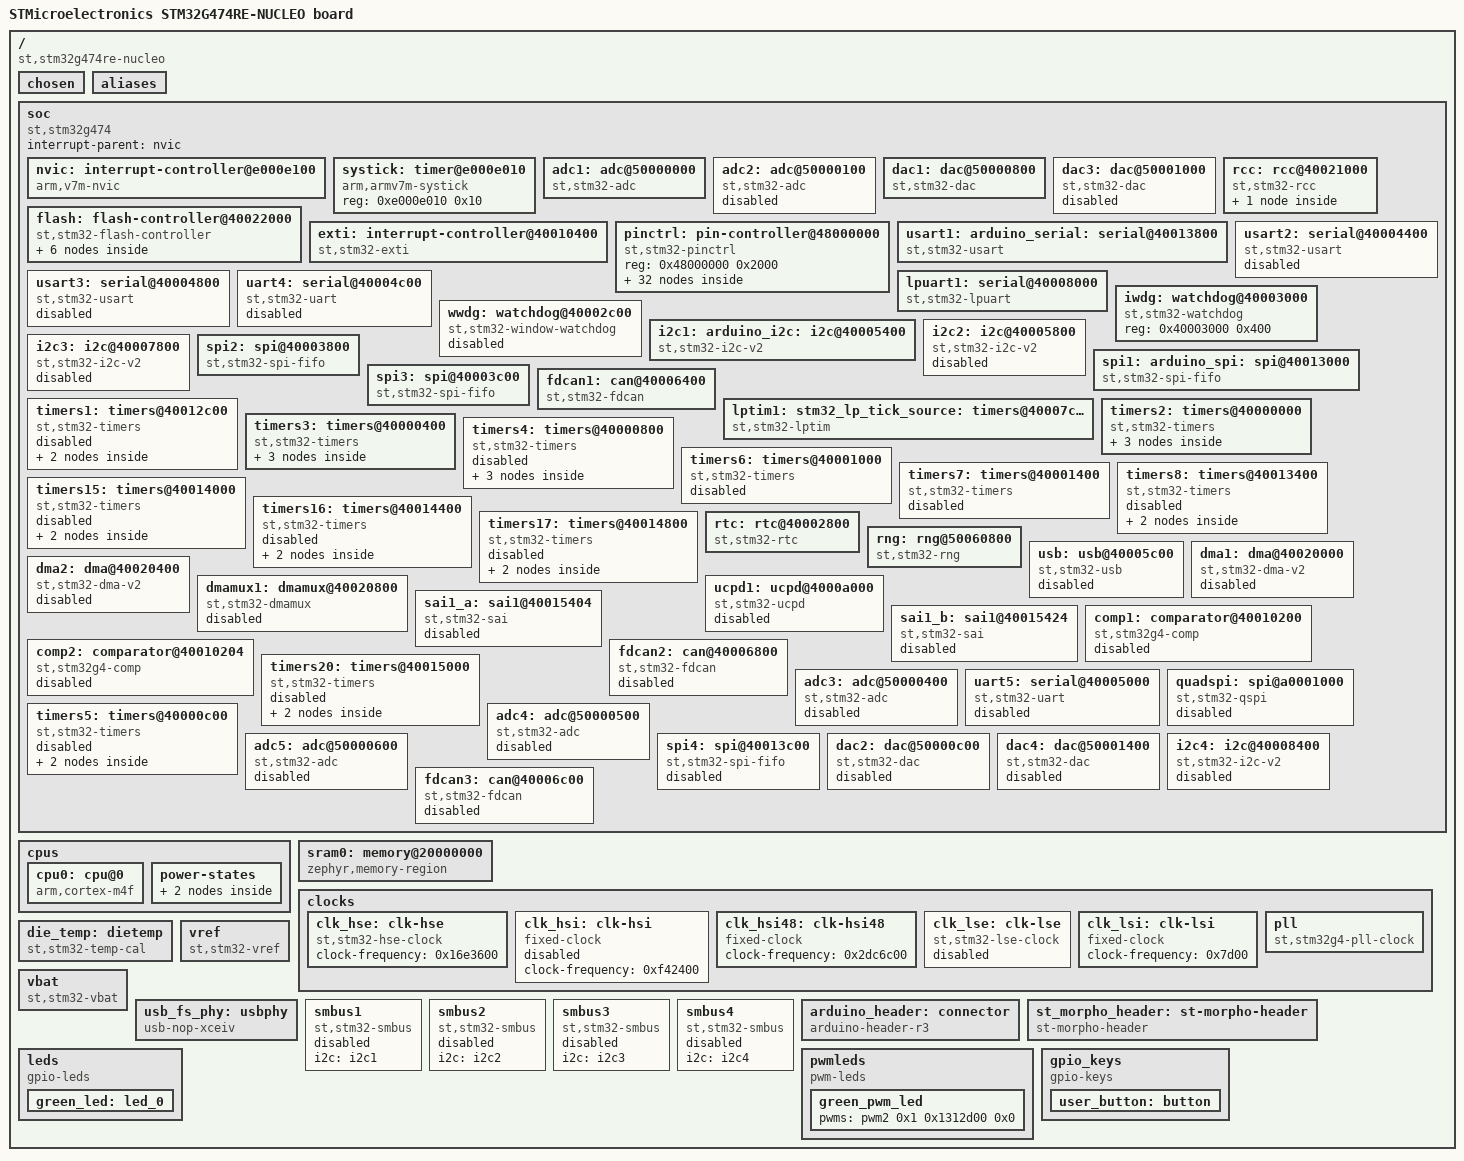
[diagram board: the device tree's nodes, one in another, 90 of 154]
/dts-v1/;

/* node '/' defined in zephyr/dts/common/skeleton.dtsi:9 */
/ {
	#address-cells = < 0x1 >;                              /* in zephyr/dts/common/skeleton.dtsi:10 */
	#size-cells = < 0x1 >;                                 /* in zephyr/dts/common/skeleton.dtsi:11 */
	model = "STMicroelectronics STM32G474RE-NUCLEO board"; /* in zephyr/boards/st/nucleo_g474re/nucleo_g474re.dts:15 */
	compatible = "st,stm32g474re-nucleo";                  /* in zephyr/boards/st/nucleo_g474re/nucleo_g474re.dts:16 */

	/* node '/chosen' defined in zephyr/dts/common/skeleton.dtsi:13 */
	chosen {
		zephyr,entropy = &rng;                    /* in zephyr/dts/arm/st/g4/stm32g4.dtsi:27 */
		zephyr,flash-controller = &flash;         /* in zephyr/dts/arm/st/g4/stm32g4.dtsi:28 */
		zephyr,console = &lpuart1;                /* in zephyr/boards/st/nucleo_g474re/nucleo_g474re.dts:19 */
		zephyr,shell-uart = &lpuart1;             /* in zephyr/boards/st/nucleo_g474re/nucleo_g474re.dts:20 */
		zephyr,sram = &sram0;                     /* in zephyr/boards/st/nucleo_g474re/nucleo_g474re.dts:21 */
		zephyr,flash = &flash0;                   /* in zephyr/boards/st/nucleo_g474re/nucleo_g474re.dts:22 */
		zephyr,canbus = &fdcan1;                  /* in zephyr/boards/st/nucleo_g474re/nucleo_g474re.dts:23 */
		zephyr,code-partition = &slot0_partition; /* in zephyr/boards/st/nucleo_g474re/nucleo_g474re.dts:24 */
	};

	/* node '/aliases' defined in zephyr/dts/common/skeleton.dtsi:15 */
	aliases {
		led0 = &green_led;         /* in zephyr/boards/st/nucleo_g474re/nucleo_g474re.dts:55 */
		mcuboot-led0 = &green_led; /* in zephyr/boards/st/nucleo_g474re/nucleo_g474re.dts:56 */
		pwm-led0 = &green_pwm_led; /* in zephyr/boards/st/nucleo_g474re/nucleo_g474re.dts:57 */
		sw0 = &user_button;        /* in zephyr/boards/st/nucleo_g474re/nucleo_g474re.dts:58 */
		watchdog0 = &iwdg;         /* in zephyr/boards/st/nucleo_g474re/nucleo_g474re.dts:59 */
		die-temp0 = &die_temp;     /* in zephyr/boards/st/nucleo_g474re/nucleo_g474re.dts:60 */
		volt-sensor0 = &vref;      /* in zephyr/boards/st/nucleo_g474re/nucleo_g474re.dts:61 */
		volt-sensor1 = &vbat;      /* in zephyr/boards/st/nucleo_g474re/nucleo_g474re.dts:62 */
	};

	/* node '/soc' defined in zephyr/dts/arm/armv7-m.dtsi:6 */
	soc {
		#address-cells = < 0x1 >;     /* in zephyr/dts/arm/armv7-m.dtsi:7 */
		#size-cells = < 0x1 >;        /* in zephyr/dts/arm/armv7-m.dtsi:8 */
		interrupt-parent = < &nvic >; /* in zephyr/dts/arm/armv7-m.dtsi:10 */
		ranges;                       /* in zephyr/dts/arm/armv7-m.dtsi:11 */
		compatible = "st,stm32g474",
		             "st,stm32g4",
		             "simple-bus";    /* in zephyr/dts/arm/st/g4/stm32g474.dtsi:11 */

		/* node '/soc/interrupt-controller@e000e100' defined in zephyr/dts/arm/armv7-m.dtsi:13 */
		nvic: interrupt-controller@e000e100 {
			#address-cells = < 0x1 >;            /* in zephyr/dts/arm/armv7-m.dtsi:14 */
			compatible = "arm,v7m-nvic";         /* in zephyr/dts/arm/armv7-m.dtsi:15 */
			reg = < 0xe000e100 0xc00 >;          /* in zephyr/dts/arm/armv7-m.dtsi:16 */
			interrupt-controller;                /* in zephyr/dts/arm/armv7-m.dtsi:17 */
			#interrupt-cells = < 0x2 >;          /* in zephyr/dts/arm/armv7-m.dtsi:18 */
			arm,num-irq-priority-bits = < 0x4 >; /* in zephyr/dts/arm/st/g4/stm32g4.dtsi:819 */
			phandle = < 0x1 >;                   /* in zephyr/dts/arm/armv7-m.dtsi:10 */
		};

		/* node '/soc/timer@e000e010' defined in zephyr/dts/arm/armv7-m.dtsi:21 */
		systick: timer@e000e010 {
			compatible = "arm,armv7m-systick"; /* in zephyr/dts/arm/armv7-m.dtsi:22 */
			reg = < 0xe000e010 0x10 >;         /* in zephyr/dts/arm/armv7-m.dtsi:23 */
		};

		/* node '/soc/adc@50000000' defined in zephyr/dts/arm/st/g4/stm32g4.dtsi:111 */
		adc1: adc@50000000 {
			compatible = "st,stm32-adc";                                /* in zephyr/dts/arm/st/g4/stm32g4.dtsi:112 */
			reg = < 0x50000000 0x100 >;                                 /* in zephyr/dts/arm/st/g4/stm32g4.dtsi:113 */
			clocks = < &rcc 0x4c 0x2000 >;                              /* in zephyr/dts/arm/st/g4/stm32g4.dtsi:114 */
			clock-names = "adcx";                                       /* in zephyr/dts/arm/st/g4/stm32g4.dtsi:115 */
			interrupts = < 0x12 0x0 >;                                  /* in zephyr/dts/arm/st/g4/stm32g4.dtsi:116 */
			#io-channel-cells = < 0x1 >;                                /* in zephyr/dts/arm/st/g4/stm32g4.dtsi:117 */
			resolutions = < 0x60630c 0x51630c 0x42630c 0x33630c >;      /* in zephyr/dts/arm/st/g4/stm32g4.dtsi:118 */
			sampling-times = < 0x3 0x7 0xd 0x19 0x30 0x5d 0xf8 0x281 >; /* in zephyr/dts/arm/st/g4/stm32g4.dtsi:122 */
			st,adc-sequencer = "programmable";                          /* in zephyr/dts/arm/st/g4/stm32g4.dtsi:123 */
			st,adc-oversampler = "minimal";                             /* in zephyr/dts/arm/st/g4/stm32g4.dtsi:124 */
			st,adc-internal-regulator = "startup-sw-delay";             /* in zephyr/dts/arm/st/g4/stm32g4.dtsi:125 */
			st,adc-has-deep-powerdown;                                  /* in zephyr/dts/arm/st/g4/stm32g4.dtsi:126 */
			st,adc-has-differential-support;                            /* in zephyr/dts/arm/st/g4/stm32g4.dtsi:127 */
			pinctrl-0 = < &adc1_in1_pa0 >;                              /* in zephyr/boards/st/nucleo_g474re/nucleo_g474re.dts:211 */
			pinctrl-names = "default";                                  /* in zephyr/boards/st/nucleo_g474re/nucleo_g474re.dts:212 */
			st,adc-clock-source = "SYNC";                               /* in zephyr/boards/st/nucleo_g474re/nucleo_g474re.dts:213 */
			st,adc-prescaler = < 0x4 >;                                 /* in zephyr/boards/st/nucleo_g474re/nucleo_g474re.dts:214 */
			status = "okay";                                            /* in zephyr/boards/st/nucleo_g474re/nucleo_g474re.dts:215 */
			phandle = < 0x24 >;                                         /* in zephyr/dts/arm/st/g4/stm32g4.dtsi:769 */
		};

		/* node '/soc/adc@50000100' defined in zephyr/dts/arm/st/g4/stm32g4.dtsi:131 */
		adc2: adc@50000100 {
			compatible = "st,stm32-adc";                                /* in zephyr/dts/arm/st/g4/stm32g4.dtsi:132 */
			reg = < 0x50000100 0x100 >;                                 /* in zephyr/dts/arm/st/g4/stm32g4.dtsi:133 */
			clocks = < &rcc 0x4c 0x2000 >;                              /* in zephyr/dts/arm/st/g4/stm32g4.dtsi:134 */
			clock-names = "adcx";                                       /* in zephyr/dts/arm/st/g4/stm32g4.dtsi:135 */
			interrupts = < 0x12 0x0 >;                                  /* in zephyr/dts/arm/st/g4/stm32g4.dtsi:136 */
			#io-channel-cells = < 0x1 >;                                /* in zephyr/dts/arm/st/g4/stm32g4.dtsi:137 */
			resolutions = < 0x60630c 0x51630c 0x42630c 0x33630c >;      /* in zephyr/dts/arm/st/g4/stm32g4.dtsi:138 */
			sampling-times = < 0x3 0x7 0xd 0x19 0x30 0x5d 0xf8 0x281 >; /* in zephyr/dts/arm/st/g4/stm32g4.dtsi:142 */
			st,adc-sequencer = "programmable";                          /* in zephyr/dts/arm/st/g4/stm32g4.dtsi:143 */
			st,adc-oversampler = "minimal";                             /* in zephyr/dts/arm/st/g4/stm32g4.dtsi:144 */
			st,adc-internal-regulator = "startup-sw-delay";             /* in zephyr/dts/arm/st/g4/stm32g4.dtsi:145 */
			st,adc-has-deep-powerdown;                                  /* in zephyr/dts/arm/st/g4/stm32g4.dtsi:146 */
			st,adc-has-differential-support;                            /* in zephyr/dts/arm/st/g4/stm32g4.dtsi:147 */
			status = "disabled";                                        /* in zephyr/dts/arm/st/g4/stm32g4.dtsi:148 */
		};

		/* node '/soc/dac@50000800' defined in zephyr/dts/arm/st/g4/stm32g4.dtsi:151 */
		dac1: dac@50000800 {
			compatible = "st,stm32-dac";    /* in zephyr/dts/arm/st/g4/stm32g4.dtsi:152 */
			reg = < 0x50000800 0x400 >;     /* in zephyr/dts/arm/st/g4/stm32g4.dtsi:153 */
			clocks = < &rcc 0x4c 0x10000 >; /* in zephyr/dts/arm/st/g4/stm32g4.dtsi:154 */
			#io-channel-cells = < 0x1 >;    /* in zephyr/dts/arm/st/g4/stm32g4.dtsi:156 */
			pinctrl-0 = < &dac1_out1_pa4 >; /* in zephyr/boards/st/nucleo_g474re/nucleo_g474re.dts:223 */
			pinctrl-names = "default";      /* in zephyr/boards/st/nucleo_g474re/nucleo_g474re.dts:224 */
			status = "okay";                /* in zephyr/boards/st/nucleo_g474re/nucleo_g474re.dts:225 */
		};

		/* node '/soc/dac@50001000' defined in zephyr/dts/arm/st/g4/stm32g4.dtsi:159 */
		dac3: dac@50001000 {
			compatible = "st,stm32-dac";    /* in zephyr/dts/arm/st/g4/stm32g4.dtsi:160 */
			reg = < 0x50001000 0x400 >;     /* in zephyr/dts/arm/st/g4/stm32g4.dtsi:161 */
			clocks = < &rcc 0x4c 0x40000 >; /* in zephyr/dts/arm/st/g4/stm32g4.dtsi:162 */
			status = "disabled";            /* in zephyr/dts/arm/st/g4/stm32g4.dtsi:163 */
			#io-channel-cells = < 0x1 >;    /* in zephyr/dts/arm/st/g4/stm32g4.dtsi:164 */
		};

		/* node '/soc/flash-controller@40022000' defined in zephyr/dts/arm/st/g4/stm32g4.dtsi:167 */
		flash: flash-controller@40022000 {
			compatible = "st,stm32-flash-controller",
			             "st,stm32g4-flash-controller"; /* in zephyr/dts/arm/st/g4/stm32g4.dtsi:168 */
			reg = < 0x40022000 0x400 >;                 /* in zephyr/dts/arm/st/g4/stm32g4.dtsi:169 */
			interrupts = < 0x3 0x0 >;                   /* in zephyr/dts/arm/st/g4/stm32g4.dtsi:170 */
			clocks = < &rcc 0x48 0x100 >;               /* in zephyr/dts/arm/st/g4/stm32g4.dtsi:171 */
			#address-cells = < 0x1 >;                   /* in zephyr/dts/arm/st/g4/stm32g4.dtsi:173 */
			#size-cells = < 0x1 >;                      /* in zephyr/dts/arm/st/g4/stm32g4.dtsi:174 */

			/* node '/soc/flash-controller@40022000/flash@8000000' defined in zephyr/dts/arm/st/g4/stm32g4.dtsi:176 */
			flash0: flash@8000000 {
				compatible = "st,stm32-nv-flash",
				             "soc-nv-flash";      /* in zephyr/dts/arm/st/g4/stm32g4.dtsi:177 */
				write-block-size = < 0x8 >;       /* in zephyr/dts/arm/st/g4/stm32g4.dtsi:179 */
				erase-block-size = < 0x800 >;     /* in zephyr/dts/arm/st/g4/stm32g4.dtsi:180 */
				max-erase-time = < 0x19 >;        /* in zephyr/dts/arm/st/g4/stm32g4.dtsi:182 */
				reg = < 0x8000000 0x80000 >;      /* in zephyr/dts/arm/st/g4/stm32g474Xe.dtsi:14 */

				/* node '/soc/flash-controller@40022000/flash@8000000/partitions' defined in zephyr/boards/st/nucleo_g474re/nucleo_g474re.dts:174 */
				partitions {
					compatible = "fixed-partitions"; /* in zephyr/boards/st/nucleo_g474re/nucleo_g474re.dts:175 */
					#address-cells = < 0x1 >;        /* in zephyr/boards/st/nucleo_g474re/nucleo_g474re.dts:176 */
					#size-cells = < 0x1 >;           /* in zephyr/boards/st/nucleo_g474re/nucleo_g474re.dts:177 */

					/* node '/soc/flash-controller@40022000/flash@8000000/partitions/partition@0' defined in zephyr/boards/st/nucleo_g474re/nucleo_g474re.dts:179 */
					boot_partition: partition@0 {
						label = "mcuboot";    /* in zephyr/boards/st/nucleo_g474re/nucleo_g474re.dts:180 */
						reg = < 0x0 0x8800 >; /* in zephyr/boards/st/nucleo_g474re/nucleo_g474re.dts:181 */
					};

					/* node '/soc/flash-controller@40022000/flash@8000000/partitions/partition@8800' defined in zephyr/boards/st/nucleo_g474re/nucleo_g474re.dts:184 */
					slot0_partition: partition@8800 {
						label = "image-0";        /* in zephyr/boards/st/nucleo_g474re/nucleo_g474re.dts:185 */
						reg = < 0x8800 0x3c000 >; /* in zephyr/boards/st/nucleo_g474re/nucleo_g474re.dts:186 */
					};

					/* node '/soc/flash-controller@40022000/flash@8000000/partitions/partition@44800' defined in zephyr/boards/st/nucleo_g474re/nucleo_g474re.dts:189 */
					slot1_partition: partition@44800 {
						label = "image-1";         /* in zephyr/boards/st/nucleo_g474re/nucleo_g474re.dts:190 */
						reg = < 0x44800 0x3a800 >; /* in zephyr/boards/st/nucleo_g474re/nucleo_g474re.dts:191 */
					};

					/* node '/soc/flash-controller@40022000/flash@8000000/partitions/partition@7f000' defined in zephyr/boards/st/nucleo_g474re/nucleo_g474re.dts:195 */
					storage_partition: partition@7f000 {
						label = "storage";        /* in zephyr/boards/st/nucleo_g474re/nucleo_g474re.dts:196 */
						reg = < 0x7f000 0x1000 >; /* in zephyr/boards/st/nucleo_g474re/nucleo_g474re.dts:197 */
					};
				};
			};
		};

		/* node '/soc/rcc@40021000' defined in zephyr/dts/arm/st/g4/stm32g4.dtsi:186 */
		rcc: rcc@40021000 {
			compatible = "st,stm32-rcc";     /* in zephyr/dts/arm/st/g4/stm32g4.dtsi:187 */
			#clock-cells = < 0x2 >;          /* in zephyr/dts/arm/st/g4/stm32g4.dtsi:188 */
			reg = < 0x40021000 0x400 >;      /* in zephyr/dts/arm/st/g4/stm32g4.dtsi:189 */
			undershoot-prevention;           /* in zephyr/dts/arm/st/g4/stm32g4.dtsi:190 */
			clocks = < &pll >;               /* in zephyr/boards/st/nucleo_g474re/nucleo_g474re.dts:90 */
			clock-frequency = < 0xa21fe80 >; /* in zephyr/boards/st/nucleo_g474re/nucleo_g474re.dts:91 */
			ahb-prescaler = < 0x1 >;         /* in zephyr/boards/st/nucleo_g474re/nucleo_g474re.dts:92 */
			apb1-prescaler = < 0x1 >;        /* in zephyr/boards/st/nucleo_g474re/nucleo_g474re.dts:93 */
			apb2-prescaler = < 0x1 >;        /* in zephyr/boards/st/nucleo_g474re/nucleo_g474re.dts:94 */
			phandle = < 0x2 >;               /* in zephyr/dts/arm/st/g4/stm32g4.dtsi:114 */

			/* node '/soc/rcc@40021000/reset-controller' defined in zephyr/dts/arm/st/g4/stm32g4.dtsi:192 */
			rctl: reset-controller {
				compatible = "st,stm32-rcc-rctl"; /* in zephyr/dts/arm/st/g4/stm32g4.dtsi:193 */
				#reset-cells = < 0x1 >;           /* in zephyr/dts/arm/st/g4/stm32g4.dtsi:194 */
				phandle = < 0x6 >;                /* in zephyr/dts/arm/st/g4/stm32g4.dtsi:281 */
			};
		};

		/* node '/soc/interrupt-controller@40010400' defined in zephyr/dts/arm/st/g4/stm32g4.dtsi:198 */
		exti: interrupt-controller@40010400 {
			compatible = "st,stm32-exti";  /* in zephyr/dts/arm/st/g4/stm32g4.dtsi:199 */
			interrupt-controller;          /* in zephyr/dts/arm/st/g4/stm32g4.dtsi:200 */
			#interrupt-cells = < 0x1 >;    /* in zephyr/dts/arm/st/g4/stm32g4.dtsi:201 */
			#address-cells = < 0x0 >;      /* in zephyr/dts/arm/st/g4/stm32g4.dtsi:202 */
			reg = < 0x40010400 0x400 >;    /* in zephyr/dts/arm/st/g4/stm32g4.dtsi:203 */
			clocks = < &rcc 0x60 0x1 >;    /* in zephyr/dts/arm/st/g4/stm32g4.dtsi:204 */
			num-lines = < 0x40 >;          /* in zephyr/dts/arm/st/g4/stm32g4.dtsi:205 */
			interrupts = < 0x6 0x0 >,
			             < 0x7 0x0 >,
			             < 0x8 0x0 >,
			             < 0x9 0x0 >,
			             < 0xa 0x0 >,
			             < 0x17 0x0 >,
			             < 0x28 0x0 >;     /* in zephyr/dts/arm/st/g4/stm32g4.dtsi:206 */
			interrupt-names = "line0",
			                  "line1",
			                  "line2-TSC",
			                  "line3",
			                  "line4",
			                  "line5-9",
			                  "line10-15"; /* in zephyr/dts/arm/st/g4/stm32g4.dtsi:208 */
			line-ranges = < 0x0 0x1 >,
			              < 0x1 0x1 >,
			              < 0x2 0x1 >,
			              < 0x3 0x1 >,
			              < 0x4 0x1 >,
			              < 0x5 0x5 >,
			              < 0xa 0x6 >;     /* in zephyr/dts/arm/st/g4/stm32g4.dtsi:210 */
		};

		/* node '/soc/pin-controller@48000000' defined in zephyr/dts/arm/st/g4/stm32g4.dtsi:214 */
		pinctrl: pin-controller@48000000 {
			compatible = "st,stm32-pinctrl"; /* in zephyr/dts/arm/st/g4/stm32g4.dtsi:215 */
			#address-cells = < 0x1 >;        /* in zephyr/dts/arm/st/g4/stm32g4.dtsi:216 */
			#size-cells = < 0x1 >;           /* in zephyr/dts/arm/st/g4/stm32g4.dtsi:217 */
			reg = < 0x48000000 0x2000 >;     /* in zephyr/dts/arm/st/g4/stm32g4.dtsi:218 */

			/* node '/soc/pin-controller@48000000/gpio@48000000' defined in zephyr/dts/arm/st/g4/stm32g4.dtsi:220 */
			gpioa: gpio@48000000 {
				compatible = "st,stm32-gpio"; /* in zephyr/dts/arm/st/g4/stm32g4.dtsi:221 */
				gpio-controller;              /* in zephyr/dts/arm/st/g4/stm32g4.dtsi:222 */
				#gpio-cells = < 0x2 >;        /* in zephyr/dts/arm/st/g4/stm32g4.dtsi:223 */
				reg = < 0x48000000 0x400 >;   /* in zephyr/dts/arm/st/g4/stm32g4.dtsi:224 */
				clocks = < &rcc 0x4c 0x1 >;   /* in zephyr/dts/arm/st/g4/stm32g4.dtsi:225 */
				phandle = < 0x29 >;           /* in zephyr/boards/st/nucleo_g474re/arduino_r3_connector.dtsi:15 */
			};

			/* node '/soc/pin-controller@48000000/gpio@48000400' defined in zephyr/dts/arm/st/g4/stm32g4.dtsi:228 */
			gpiob: gpio@48000400 {
				compatible = "st,stm32-gpio"; /* in zephyr/dts/arm/st/g4/stm32g4.dtsi:229 */
				gpio-controller;              /* in zephyr/dts/arm/st/g4/stm32g4.dtsi:230 */
				#gpio-cells = < 0x2 >;        /* in zephyr/dts/arm/st/g4/stm32g4.dtsi:231 */
				reg = < 0x48000400 0x400 >;   /* in zephyr/dts/arm/st/g4/stm32g4.dtsi:232 */
				clocks = < &rcc 0x4c 0x2 >;   /* in zephyr/dts/arm/st/g4/stm32g4.dtsi:233 */
				phandle = < 0x12 >;           /* in zephyr/boards/st/nucleo_g474re/nucleo_g474re.dts:121 */
			};

			/* node '/soc/pin-controller@48000000/gpio@48000800' defined in zephyr/dts/arm/st/g4/stm32g4.dtsi:236 */
			gpioc: gpio@48000800 {
				compatible = "st,stm32-gpio"; /* in zephyr/dts/arm/st/g4/stm32g4.dtsi:237 */
				gpio-controller;              /* in zephyr/dts/arm/st/g4/stm32g4.dtsi:238 */
				#gpio-cells = < 0x2 >;        /* in zephyr/dts/arm/st/g4/stm32g4.dtsi:239 */
				reg = < 0x48000800 0x400 >;   /* in zephyr/dts/arm/st/g4/stm32g4.dtsi:240 */
				clocks = < &rcc 0x4c 0x4 >;   /* in zephyr/dts/arm/st/g4/stm32g4.dtsi:241 */
				phandle = < 0x2a >;           /* in zephyr/boards/st/nucleo_g474re/arduino_r3_connector.dtsi:15 */
			};

			/* node '/soc/pin-controller@48000000/gpio@48000c00' defined in zephyr/dts/arm/st/g4/stm32g4.dtsi:244 */
			gpiod: gpio@48000c00 {
				compatible = "st,stm32-gpio"; /* in zephyr/dts/arm/st/g4/stm32g4.dtsi:245 */
				gpio-controller;              /* in zephyr/dts/arm/st/g4/stm32g4.dtsi:246 */
				#gpio-cells = < 0x2 >;        /* in zephyr/dts/arm/st/g4/stm32g4.dtsi:247 */
				reg = < 0x48000c00 0x400 >;   /* in zephyr/dts/arm/st/g4/stm32g4.dtsi:248 */
				clocks = < &rcc 0x4c 0x8 >;   /* in zephyr/dts/arm/st/g4/stm32g4.dtsi:249 */
				phandle = < 0x2b >;           /* in zephyr/boards/st/nucleo_g474re/st_morpho_connector.dtsi:15 */
			};

			/* node '/soc/pin-controller@48000000/gpio@48001000' defined in zephyr/dts/arm/st/g4/stm32g4.dtsi:252 */
			gpioe: gpio@48001000 {
				compatible = "st,stm32-gpio"; /* in zephyr/dts/arm/st/g4/stm32g4.dtsi:253 */
				gpio-controller;              /* in zephyr/dts/arm/st/g4/stm32g4.dtsi:254 */
				#gpio-cells = < 0x2 >;        /* in zephyr/dts/arm/st/g4/stm32g4.dtsi:255 */
				reg = < 0x48001000 0x400 >;   /* in zephyr/dts/arm/st/g4/stm32g4.dtsi:256 */
				clocks = < &rcc 0x4c 0x10 >;  /* in zephyr/dts/arm/st/g4/stm32g4.dtsi:257 */
			};

			/* node '/soc/pin-controller@48000000/gpio@48001400' defined in zephyr/dts/arm/st/g4/stm32g4.dtsi:260 */
			gpiof: gpio@48001400 {
				compatible = "st,stm32-gpio"; /* in zephyr/dts/arm/st/g4/stm32g4.dtsi:261 */
				gpio-controller;              /* in zephyr/dts/arm/st/g4/stm32g4.dtsi:262 */
				#gpio-cells = < 0x2 >;        /* in zephyr/dts/arm/st/g4/stm32g4.dtsi:263 */
				reg = < 0x48001400 0x400 >;   /* in zephyr/dts/arm/st/g4/stm32g4.dtsi:264 */
				clocks = < &rcc 0x4c 0x20 >;  /* in zephyr/dts/arm/st/g4/stm32g4.dtsi:265 */
				phandle = < 0x2c >;           /* in zephyr/boards/st/nucleo_g474re/st_morpho_connector.dtsi:15 */
			};

			/* node '/soc/pin-controller@48000000/gpio@48001800' defined in zephyr/dts/arm/st/g4/stm32g4.dtsi:268 */
			gpiog: gpio@48001800 {
				compatible = "st,stm32-gpio"; /* in zephyr/dts/arm/st/g4/stm32g4.dtsi:269 */
				gpio-controller;              /* in zephyr/dts/arm/st/g4/stm32g4.dtsi:270 */
				#gpio-cells = < 0x2 >;        /* in zephyr/dts/arm/st/g4/stm32g4.dtsi:271 */
				reg = < 0x48001800 0x400 >;   /* in zephyr/dts/arm/st/g4/stm32g4.dtsi:272 */
				clocks = < &rcc 0x4c 0x40 >;  /* in zephyr/dts/arm/st/g4/stm32g4.dtsi:273 */
			};

			/* node '/soc/pin-controller@48000000/adc1_in1_pa0' defined in modules/hal/stm32/dts/st/g4/stm32g474r(b-c-e)tx-pinctrl.dtsi:15 */
			adc1_in1_pa0: adc1_in1_pa0 {
				pinmux = < 0x10 >; /* in modules/hal/stm32/dts/st/g4/stm32g474r(b-c-e)tx-pinctrl.dtsi:16 */
				phandle = < 0x3 >; /* in zephyr/boards/st/nucleo_g474re/nucleo_g474re.dts:211 */
			};

			/* node '/soc/pin-controller@48000000/analog_pa2' defined in modules/hal/stm32/dts/st/g4/stm32g474r(b-c-e)tx-pinctrl.dtsi:177 */
			analog_pa2: analog_pa2 {
				pinmux = < 0x50 >; /* in modules/hal/stm32/dts/st/g4/stm32g474r(b-c-e)tx-pinctrl.dtsi:178 */
				phandle = < 0xb >; /* in zephyr/boards/st/nucleo_g474re/nucleo_g474re.dts:106 */
			};

			/* node '/soc/pin-controller@48000000/analog_pa3' defined in modules/hal/stm32/dts/st/g4/stm32g474r(b-c-e)tx-pinctrl.dtsi:181 */
			analog_pa3: analog_pa3 {
				pinmux = < 0x70 >; /* in modules/hal/stm32/dts/st/g4/stm32g474r(b-c-e)tx-pinctrl.dtsi:182 */
				phandle = < 0xc >; /* in zephyr/boards/st/nucleo_g474re/nucleo_g474re.dts:106 */
			};

			/* node '/soc/pin-controller@48000000/dac1_out1_pa4' defined in modules/hal/stm32/dts/st/g4/stm32g474r(b-c-e)tx-pinctrl.dtsi:543 */
			dac1_out1_pa4: dac1_out1_pa4 {
				pinmux = < 0x90 >; /* in modules/hal/stm32/dts/st/g4/stm32g474r(b-c-e)tx-pinctrl.dtsi:544 */
				phandle = < 0x4 >; /* in zephyr/boards/st/nucleo_g474re/nucleo_g474re.dts:223 */
			};

			/* node '/soc/pin-controller@48000000/fdcan1_rx_pa11' defined in modules/hal/stm32/dts/st/g4/stm32g474r(b-c-e)tx-pinctrl.dtsi:557 */
			fdcan1_rx_pa11: fdcan1_rx_pa11 {
				pinmux = < 0x169 >; /* in modules/hal/stm32/dts/st/g4/stm32g474r(b-c-e)tx-pinctrl.dtsi:558 */
				phandle = < 0x1b >; /* in zephyr/boards/st/nucleo_g474re/nucleo_g474re.dts:231 */
			};

			/* node '/soc/pin-controller@48000000/fdcan1_tx_pa12' defined in modules/hal/stm32/dts/st/g4/stm32g474r(b-c-e)tx-pinctrl.dtsi:583 */
			fdcan1_tx_pa12: fdcan1_tx_pa12 {
				pinmux = < 0x189 >; /* in modules/hal/stm32/dts/st/g4/stm32g474r(b-c-e)tx-pinctrl.dtsi:584 */
				phandle = < 0x1c >; /* in zephyr/boards/st/nucleo_g474re/nucleo_g474re.dts:231 */
			};

			/* node '/soc/pin-controller@48000000/i2c1_scl_pb8' defined in modules/hal/stm32/dts/st/g4/stm32g474r(b-c-e)tx-pinctrl.dtsi:735 */
			i2c1_scl_pb8: i2c1_scl_pb8 {
				pinmux = < 0x304 >; /* in modules/hal/stm32/dts/st/g4/stm32g474r(b-c-e)tx-pinctrl.dtsi:736 */
				bias-pull-up;       /* in modules/hal/stm32/dts/st/g4/stm32g474r(b-c-e)tx-pinctrl.dtsi:737 */
				drive-open-drain;   /* in modules/hal/stm32/dts/st/g4/stm32g474r(b-c-e)tx-pinctrl.dtsi:738 */
				phandle = < 0xd >;  /* in zephyr/boards/st/nucleo_g474re/nucleo_g474re.dts:113 */
			};

			/* node '/soc/pin-controller@48000000/i2c1_sda_pb9' defined in modules/hal/stm32/dts/st/g4/stm32g474r(b-c-e)tx-pinctrl.dtsi:791 */
			i2c1_sda_pb9: i2c1_sda_pb9 {
				pinmux = < 0x324 >; /* in modules/hal/stm32/dts/st/g4/stm32g474r(b-c-e)tx-pinctrl.dtsi:792 */
				bias-pull-up;       /* in modules/hal/stm32/dts/st/g4/stm32g474r(b-c-e)tx-pinctrl.dtsi:793 */
				drive-open-drain;   /* in modules/hal/stm32/dts/st/g4/stm32g474r(b-c-e)tx-pinctrl.dtsi:794 */
				phandle = < 0xe >;  /* in zephyr/boards/st/nucleo_g474re/nucleo_g474re.dts:113 */
			};

			/* node '/soc/pin-controller@48000000/spi1_miso_pa6' defined in modules/hal/stm32/dts/st/g4/stm32g474r(b-c-e)tx-pinctrl.dtsi:1278 */
			spi1_miso_pa6: spi1_miso_pa6 {
				pinmux = < 0xc5 >;  /* in modules/hal/stm32/dts/st/g4/stm32g474r(b-c-e)tx-pinctrl.dtsi:1279 */
				bias-pull-down;     /* in modules/hal/stm32/dts/st/g4/stm32g474r(b-c-e)tx-pinctrl.dtsi:1280 */
				phandle = < 0x10 >; /* in zephyr/boards/st/nucleo_g474re/nucleo_g474re.dts:119 */
			};

			/* node '/soc/pin-controller@48000000/spi2_miso_pb14' defined in modules/hal/stm32/dts/st/g4/stm32g474r(b-c-e)tx-pinctrl.dtsi:1293 */
			spi2_miso_pb14: spi2_miso_pb14 {
				pinmux = < 0x3c5 >; /* in modules/hal/stm32/dts/st/g4/stm32g474r(b-c-e)tx-pinctrl.dtsi:1294 */
				bias-pull-down;     /* in modules/hal/stm32/dts/st/g4/stm32g474r(b-c-e)tx-pinctrl.dtsi:1295 */
				phandle = < 0x15 >; /* in zephyr/boards/st/nucleo_g474re/nucleo_g474re.dts:126 */
			};

			/* node '/soc/pin-controller@48000000/spi3_miso_pc11' defined in modules/hal/stm32/dts/st/g4/stm32g474r(b-c-e)tx-pinctrl.dtsi:1303 */
			spi3_miso_pc11: spi3_miso_pc11 {
				pinmux = < 0x566 >; /* in modules/hal/stm32/dts/st/g4/stm32g474r(b-c-e)tx-pinctrl.dtsi:1304 */
				bias-pull-down;     /* in modules/hal/stm32/dts/st/g4/stm32g474r(b-c-e)tx-pinctrl.dtsi:1305 */
				phandle = < 0x19 >; /* in zephyr/boards/st/nucleo_g474re/nucleo_g474re.dts:134 */
			};

			/* node '/soc/pin-controller@48000000/spi1_mosi_pa7' defined in modules/hal/stm32/dts/st/g4/stm32g474r(b-c-e)tx-pinctrl.dtsi:1310 */
			spi1_mosi_pa7: spi1_mosi_pa7 {
				pinmux = < 0xe5 >;  /* in modules/hal/stm32/dts/st/g4/stm32g474r(b-c-e)tx-pinctrl.dtsi:1311 */
				bias-pull-down;     /* in modules/hal/stm32/dts/st/g4/stm32g474r(b-c-e)tx-pinctrl.dtsi:1312 */
				phandle = < 0x11 >; /* in zephyr/boards/st/nucleo_g474re/nucleo_g474re.dts:119 */
			};

			/* node '/soc/pin-controller@48000000/spi2_mosi_pb15' defined in modules/hal/stm32/dts/st/g4/stm32g474r(b-c-e)tx-pinctrl.dtsi:1325 */
			spi2_mosi_pb15: spi2_mosi_pb15 {
				pinmux = < 0x3e5 >; /* in modules/hal/stm32/dts/st/g4/stm32g474r(b-c-e)tx-pinctrl.dtsi:1326 */
				bias-pull-down;     /* in modules/hal/stm32/dts/st/g4/stm32g474r(b-c-e)tx-pinctrl.dtsi:1327 */
				phandle = < 0x16 >; /* in zephyr/boards/st/nucleo_g474re/nucleo_g474re.dts:126 */
			};

			/* node '/soc/pin-controller@48000000/spi3_mosi_pc12' defined in modules/hal/stm32/dts/st/g4/stm32g474r(b-c-e)tx-pinctrl.dtsi:1335 */
			spi3_mosi_pc12: spi3_mosi_pc12 {
				pinmux = < 0x586 >; /* in modules/hal/stm32/dts/st/g4/stm32g474r(b-c-e)tx-pinctrl.dtsi:1336 */
				bias-pull-down;     /* in modules/hal/stm32/dts/st/g4/stm32g474r(b-c-e)tx-pinctrl.dtsi:1337 */
				phandle = < 0x1a >; /* in zephyr/boards/st/nucleo_g474re/nucleo_g474re.dts:134 */
			};

			/* node '/soc/pin-controller@48000000/spi2_nss_pb12' defined in modules/hal/stm32/dts/st/g4/stm32g474r(b-c-e)tx-pinctrl.dtsi:1352 */
			spi2_nss_pb12: spi2_nss_pb12 {
				pinmux = < 0x385 >; /* in modules/hal/stm32/dts/st/g4/stm32g474r(b-c-e)tx-pinctrl.dtsi:1353 */
				bias-pull-up;       /* in modules/hal/stm32/dts/st/g4/stm32g474r(b-c-e)tx-pinctrl.dtsi:1354 */
				phandle = < 0x13 >; /* in zephyr/boards/st/nucleo_g474re/nucleo_g474re.dts:126 */
			};

			/* node '/soc/pin-controller@48000000/spi3_nss_pa15' defined in modules/hal/stm32/dts/st/g4/stm32g474r(b-c-e)tx-pinctrl.dtsi:1367 */
			spi3_nss_pa15: spi3_nss_pa15 {
				pinmux = < 0x1e6 >; /* in modules/hal/stm32/dts/st/g4/stm32g474r(b-c-e)tx-pinctrl.dtsi:1368 */
				bias-pull-up;       /* in modules/hal/stm32/dts/st/g4/stm32g474r(b-c-e)tx-pinctrl.dtsi:1369 */
				phandle = < 0x17 >; /* in zephyr/boards/st/nucleo_g474re/nucleo_g474re.dts:134 */
			};

			/* node '/soc/pin-controller@48000000/spi1_sck_pa5' defined in modules/hal/stm32/dts/st/g4/stm32g474r(b-c-e)tx-pinctrl.dtsi:1374 */
			spi1_sck_pa5: spi1_sck_pa5 {
				pinmux = < 0xa5 >;             /* in modules/hal/stm32/dts/st/g4/stm32g474r(b-c-e)tx-pinctrl.dtsi:1375 */
				bias-pull-down;                /* in modules/hal/stm32/dts/st/g4/stm32g474r(b-c-e)tx-pinctrl.dtsi:1376 */
				slew-rate = "very-high-speed"; /* in modules/hal/stm32/dts/st/g4/stm32g474r(b-c-e)tx-pinctrl.dtsi:1377 */
				phandle = < 0xf >;             /* in zephyr/boards/st/nucleo_g474re/nucleo_g474re.dts:119 */
			};

			/* node '/soc/pin-controller@48000000/spi2_sck_pb13' defined in modules/hal/stm32/dts/st/g4/stm32g474r(b-c-e)tx-pinctrl.dtsi:1386 */
			spi2_sck_pb13: spi2_sck_pb13 {
				pinmux = < 0x3a5 >;            /* in modules/hal/stm32/dts/st/g4/stm32g474r(b-c-e)tx-pinctrl.dtsi:1387 */
				bias-pull-down;                /* in modules/hal/stm32/dts/st/g4/stm32g474r(b-c-e)tx-pinctrl.dtsi:1388 */
				slew-rate = "very-high-speed"; /* in modules/hal/stm32/dts/st/g4/stm32g474r(b-c-e)tx-pinctrl.dtsi:1389 */
				phandle = < 0x14 >;            /* in zephyr/boards/st/nucleo_g474re/nucleo_g474re.dts:126 */
			};

			/* node '/soc/pin-controller@48000000/spi3_sck_pc10' defined in modules/hal/stm32/dts/st/g4/stm32g474r(b-c-e)tx-pinctrl.dtsi:1404 */
			spi3_sck_pc10: spi3_sck_pc10 {
				pinmux = < 0x546 >;            /* in modules/hal/stm32/dts/st/g4/stm32g474r(b-c-e)tx-pinctrl.dtsi:1405 */
				bias-pull-down;                /* in modules/hal/stm32/dts/st/g4/stm32g474r(b-c-e)tx-pinctrl.dtsi:1406 */
				slew-rate = "very-high-speed"; /* in modules/hal/stm32/dts/st/g4/stm32g474r(b-c-e)tx-pinctrl.dtsi:1407 */
				phandle = < 0x18 >;            /* in zephyr/boards/st/nucleo_g474re/nucleo_g474re.dts:134 */
			};

			/* node '/soc/pin-controller@48000000/tim2_ch1_pa5' defined in modules/hal/stm32/dts/st/g4/stm32g474r(b-c-e)tx-pinctrl.dtsi:1606 */
			tim2_ch1_pa5: tim2_ch1_pa5 {
				pinmux = < 0xa1 >;  /* in modules/hal/stm32/dts/st/g4/stm32g474r(b-c-e)tx-pinctrl.dtsi:1607 */
				phandle = < 0x1d >; /* in zephyr/boards/st/nucleo_g474re/nucleo_g474re.dts:145 */
			};

			/* node '/soc/pin-controller@48000000/tim3_ch1_pb4' defined in modules/hal/stm32/dts/st/g4/stm32g474r(b-c-e)tx-pinctrl.dtsi:1654 */
			tim3_ch1_pb4: tim3_ch1_pb4 {
				pinmux = < 0x282 >; /* in modules/hal/stm32/dts/st/g4/stm32g474r(b-c-e)tx-pinctrl.dtsi:1655 */
				phandle = < 0x1e >; /* in zephyr/boards/st/nucleo_g474re/nucleo_g474re.dts:156 */
			};

			/* node '/soc/pin-controller@48000000/lpuart1_rx_pa3' defined in modules/hal/stm32/dts/st/g4/stm32g474r(b-c-e)tx-pinctrl.dtsi:1992 */
			lpuart1_rx_pa3: lpuart1_rx_pa3 {
				pinmux = < 0x6c >; /* in modules/hal/stm32/dts/st/g4/stm32g474r(b-c-e)tx-pinctrl.dtsi:1993 */
				phandle = < 0xa >; /* in zephyr/boards/st/nucleo_g474re/nucleo_g474re.dts:105 */
			};

			/* node '/soc/pin-controller@48000000/usart1_rx_pc5' defined in modules/hal/stm32/dts/st/g4/stm32g474r(b-c-e)tx-pinctrl.dtsi:2012 */
			usart1_rx_pc5: usart1_rx_pc5 {
				pinmux = < 0x4a7 >; /* in modules/hal/stm32/dts/st/g4/stm32g474r(b-c-e)tx-pinctrl.dtsi:2013 */
				phandle = < 0x8 >;  /* in zephyr/boards/st/nucleo_g474re/nucleo_g474re.dts:98 */
			};

			/* node '/soc/pin-controller@48000000/lpuart1_tx_pa2' defined in modules/hal/stm32/dts/st/g4/stm32g474r(b-c-e)tx-pinctrl.dtsi:2050 */
			lpuart1_tx_pa2: lpuart1_tx_pa2 {
				pinmux = < 0x4c >; /* in modules/hal/stm32/dts/st/g4/stm32g474r(b-c-e)tx-pinctrl.dtsi:2051 */
				bias-pull-up;      /* in modules/hal/stm32/dts/st/g4/stm32g474r(b-c-e)tx-pinctrl.dtsi:2052 */
				phandle = < 0x9 >; /* in zephyr/boards/st/nucleo_g474re/nucleo_g474re.dts:105 */
			};

			/* node '/soc/pin-controller@48000000/usart1_tx_pc4' defined in modules/hal/stm32/dts/st/g4/stm32g474r(b-c-e)tx-pinctrl.dtsi:2075 */
			usart1_tx_pc4: usart1_tx_pc4 {
				pinmux = < 0x487 >; /* in modules/hal/stm32/dts/st/g4/stm32g474r(b-c-e)tx-pinctrl.dtsi:2076 */
				bias-pull-up;       /* in modules/hal/stm32/dts/st/g4/stm32g474r(b-c-e)tx-pinctrl.dtsi:2077 */
				phandle = < 0x7 >;  /* in zephyr/boards/st/nucleo_g474re/nucleo_g474re.dts:98 */
			};
		};

		/* node '/soc/serial@40013800' defined in zephyr/dts/arm/st/g4/stm32g4.dtsi:277 */
		usart1: arduino_serial: serial@40013800 {
			compatible = "st,stm32-usart",
			             "st,stm32-uart";                  /* in zephyr/dts/arm/st/g4/stm32g4.dtsi:278 */
			reg = < 0x40013800 0x400 >;                    /* in zephyr/dts/arm/st/g4/stm32g4.dtsi:279 */
			clocks = < &rcc 0x60 0x4000 >;                 /* in zephyr/dts/arm/st/g4/stm32g4.dtsi:280 */
			resets = < &rctl 0x80e >;                      /* in zephyr/dts/arm/st/g4/stm32g4.dtsi:281 */
			interrupts = < 0x25 0x0 >;                     /* in zephyr/dts/arm/st/g4/stm32g4.dtsi:282 */
			pinctrl-0 = < &usart1_tx_pc4 &usart1_rx_pc5 >; /* in zephyr/boards/st/nucleo_g474re/nucleo_g474re.dts:98 */
			pinctrl-names = "default";                     /* in zephyr/boards/st/nucleo_g474re/nucleo_g474re.dts:99 */
			current-speed = < 0x1c200 >;                   /* in zephyr/boards/st/nucleo_g474re/nucleo_g474re.dts:100 */
			status = "okay";                               /* in zephyr/boards/st/nucleo_g474re/nucleo_g474re.dts:101 */
		};

		/* node '/soc/serial@40004400' defined in zephyr/dts/arm/st/g4/stm32g4.dtsi:286 */
		usart2: serial@40004400 {
			compatible = "st,stm32-usart",
			             "st,stm32-uart";   /* in zephyr/dts/arm/st/g4/stm32g4.dtsi:287 */
			reg = < 0x40004400 0x400 >;     /* in zephyr/dts/arm/st/g4/stm32g4.dtsi:288 */
			clocks = < &rcc 0x58 0x20000 >; /* in zephyr/dts/arm/st/g4/stm32g4.dtsi:289 */
			resets = < &rctl 0x711 >;       /* in zephyr/dts/arm/st/g4/stm32g4.dtsi:290 */
			interrupts = < 0x26 0x0 >;      /* in zephyr/dts/arm/st/g4/stm32g4.dtsi:291 */
			status = "disabled";            /* in zephyr/dts/arm/st/g4/stm32g4.dtsi:292 */
		};

		/* node '/soc/serial@40004800' defined in zephyr/dts/arm/st/g4/stm32g4.dtsi:295 */
		usart3: serial@40004800 {
			compatible = "st,stm32-usart",
			             "st,stm32-uart";   /* in zephyr/dts/arm/st/g4/stm32g4.dtsi:296 */
			reg = < 0x40004800 0x400 >;     /* in zephyr/dts/arm/st/g4/stm32g4.dtsi:297 */
			clocks = < &rcc 0x58 0x40000 >; /* in zephyr/dts/arm/st/g4/stm32g4.dtsi:298 */
			resets = < &rctl 0x712 >;       /* in zephyr/dts/arm/st/g4/stm32g4.dtsi:299 */
			interrupts = < 0x27 0x0 >;      /* in zephyr/dts/arm/st/g4/stm32g4.dtsi:300 */
			status = "disabled";            /* in zephyr/dts/arm/st/g4/stm32g4.dtsi:301 */
		};

		/* node '/soc/serial@40004c00' defined in zephyr/dts/arm/st/g4/stm32g4.dtsi:304 */
		uart4: serial@40004c00 {
			compatible = "st,stm32-uart";   /* in zephyr/dts/arm/st/g4/stm32g4.dtsi:305 */
			reg = < 0x40004c00 0x400 >;     /* in zephyr/dts/arm/st/g4/stm32g4.dtsi:306 */
			clocks = < &rcc 0x58 0x80000 >; /* in zephyr/dts/arm/st/g4/stm32g4.dtsi:307 */
			resets = < &rctl 0x713 >;       /* in zephyr/dts/arm/st/g4/stm32g4.dtsi:308 */
			interrupts = < 0x34 0x0 >;      /* in zephyr/dts/arm/st/g4/stm32g4.dtsi:309 */
			status = "disabled";            /* in zephyr/dts/arm/st/g4/stm32g4.dtsi:310 */
		};

		/* node '/soc/serial@40008000' defined in zephyr/dts/arm/st/g4/stm32g4.dtsi:313 */
		lpuart1: serial@40008000 {
			compatible = "st,stm32-lpuart",
			             "st,stm32-uart";                    /* in zephyr/dts/arm/st/g4/stm32g4.dtsi:314 */
			reg = < 0x40008000 0x400 >;                      /* in zephyr/dts/arm/st/g4/stm32g4.dtsi:315 */
			clocks = < &rcc 0x5c 0x1 >;                      /* in zephyr/dts/arm/st/g4/stm32g4.dtsi:316 */
			resets = < &rctl 0x780 >;                        /* in zephyr/dts/arm/st/g4/stm32g4.dtsi:317 */
			interrupts = < 0x5b 0x0 >;                       /* in zephyr/dts/arm/st/g4/stm32g4.dtsi:318 */
			pinctrl-0 = < &lpuart1_tx_pa2 &lpuart1_rx_pa3 >; /* in zephyr/boards/st/nucleo_g474re/nucleo_g474re.dts:105 */
			pinctrl-1 = < &analog_pa2 &analog_pa3 >;         /* in zephyr/boards/st/nucleo_g474re/nucleo_g474re.dts:106 */
			pinctrl-names = "default",
			                "sleep";                         /* in zephyr/boards/st/nucleo_g474re/nucleo_g474re.dts:107 */
			current-speed = < 0x1c200 >;                     /* in zephyr/boards/st/nucleo_g474re/nucleo_g474re.dts:108 */
			status = "okay";                                 /* in zephyr/boards/st/nucleo_g474re/nucleo_g474re.dts:109 */
		};

		/* node '/soc/watchdog@40003000' defined in zephyr/dts/arm/st/g4/stm32g4.dtsi:322 */
		iwdg: watchdog@40003000 {
			compatible = "st,stm32-watchdog"; /* in zephyr/dts/arm/st/g4/stm32g4.dtsi:323 */
			reg = < 0x40003000 0x400 >;       /* in zephyr/dts/arm/st/g4/stm32g4.dtsi:324 */
			status = "okay";                  /* in zephyr/boards/st/nucleo_g474re/nucleo_g474re.dts:203 */
		};

		/* node '/soc/watchdog@40002c00' defined in zephyr/dts/arm/st/g4/stm32g4.dtsi:328 */
		wwdg: watchdog@40002c00 {
			compatible = "st,stm32-window-watchdog"; /* in zephyr/dts/arm/st/g4/stm32g4.dtsi:329 */
			reg = < 0x40002c00 0x400 >;              /* in zephyr/dts/arm/st/g4/stm32g4.dtsi:330 */
			clocks = < &rcc 0x58 0x800 >;            /* in zephyr/dts/arm/st/g4/stm32g4.dtsi:331 */
			interrupts = < 0x0 0x7 >;                /* in zephyr/dts/arm/st/g4/stm32g4.dtsi:332 */
			status = "disabled";                     /* in zephyr/dts/arm/st/g4/stm32g4.dtsi:333 */
		};

		/* node '/soc/i2c@40005400' defined in zephyr/dts/arm/st/g4/stm32g4.dtsi:336 */
		i2c1: arduino_i2c: i2c@40005400 {
			compatible = "st,stm32-i2c-v2";              /* in zephyr/dts/arm/st/g4/stm32g4.dtsi:337 */
			clock-frequency = < 0x186a0 >;               /* in zephyr/dts/arm/st/g4/stm32g4.dtsi:338 */
			#address-cells = < 0x1 >;                    /* in zephyr/dts/arm/st/g4/stm32g4.dtsi:339 */
			#size-cells = < 0x0 >;                       /* in zephyr/dts/arm/st/g4/stm32g4.dtsi:340 */
			reg = < 0x40005400 0x400 >;                  /* in zephyr/dts/arm/st/g4/stm32g4.dtsi:341 */
			clocks = < &rcc 0x58 0x200000 >;             /* in zephyr/dts/arm/st/g4/stm32g4.dtsi:342 */
			interrupts = < 0x1f 0x0 >,
			             < 0x20 0x0 >;                   /* in zephyr/dts/arm/st/g4/stm32g4.dtsi:343 */
			interrupt-names = "event",
			                  "error";                   /* in zephyr/dts/arm/st/g4/stm32g4.dtsi:344 */
			pinctrl-0 = < &i2c1_scl_pb8 &i2c1_sda_pb9 >; /* in zephyr/boards/st/nucleo_g474re/nucleo_g474re.dts:113 */
			pinctrl-names = "default";                   /* in zephyr/boards/st/nucleo_g474re/nucleo_g474re.dts:114 */
			status = "okay";                             /* in zephyr/boards/st/nucleo_g474re/nucleo_g474re.dts:115 */
			phandle = < 0x25 >;                          /* in zephyr/dts/arm/st/g4/stm32g4.dtsi:797 */
		};

		/* node '/soc/i2c@40005800' defined in zephyr/dts/arm/st/g4/stm32g4.dtsi:348 */
		i2c2: i2c@40005800 {
			compatible = "st,stm32-i2c-v2";  /* in zephyr/dts/arm/st/g4/stm32g4.dtsi:349 */
			clock-frequency = < 0x186a0 >;   /* in zephyr/dts/arm/st/g4/stm32g4.dtsi:350 */
			#address-cells = < 0x1 >;        /* in zephyr/dts/arm/st/g4/stm32g4.dtsi:351 */
			#size-cells = < 0x0 >;           /* in zephyr/dts/arm/st/g4/stm32g4.dtsi:352 */
			reg = < 0x40005800 0x400 >;      /* in zephyr/dts/arm/st/g4/stm32g4.dtsi:353 */
			clocks = < &rcc 0x58 0x400000 >; /* in zephyr/dts/arm/st/g4/stm32g4.dtsi:354 */
			interrupts = < 0x21 0x0 >,
			             < 0x22 0x0 >;       /* in zephyr/dts/arm/st/g4/stm32g4.dtsi:355 */
			interrupt-names = "event",
			                  "error";       /* in zephyr/dts/arm/st/g4/stm32g4.dtsi:356 */
			status = "disabled";             /* in zephyr/dts/arm/st/g4/stm32g4.dtsi:357 */
			phandle = < 0x26 >;              /* in zephyr/dts/arm/st/g4/stm32g4.dtsi:805 */
		};

		/* node '/soc/i2c@40007800' defined in zephyr/dts/arm/st/g4/stm32g4.dtsi:360 */
		i2c3: i2c@40007800 {
			compatible = "st,stm32-i2c-v2";    /* in zephyr/dts/arm/st/g4/stm32g4.dtsi:361 */
			clock-frequency = < 0x186a0 >;     /* in zephyr/dts/arm/st/g4/stm32g4.dtsi:362 */
			#address-cells = < 0x1 >;          /* in zephyr/dts/arm/st/g4/stm32g4.dtsi:363 */
			#size-cells = < 0x0 >;             /* in zephyr/dts/arm/st/g4/stm32g4.dtsi:364 */
			reg = < 0x40007800 0x400 >;        /* in zephyr/dts/arm/st/g4/stm32g4.dtsi:365 */
			clocks = < &rcc 0x58 0x40000000 >; /* in zephyr/dts/arm/st/g4/stm32g4.dtsi:366 */
			interrupts = < 0x5c 0x0 >,
			             < 0x5d 0x0 >;         /* in zephyr/dts/arm/st/g4/stm32g4.dtsi:367 */
			interrupt-names = "event",
			                  "error";         /* in zephyr/dts/arm/st/g4/stm32g4.dtsi:368 */
			status = "disabled";               /* in zephyr/dts/arm/st/g4/stm32g4.dtsi:369 */
			phandle = < 0x27 >;                /* in zephyr/dts/arm/st/g4/stm32g4.dtsi:813 */
		};

		/* node '/soc/spi@40013000' defined in zephyr/dts/arm/st/g4/stm32g4.dtsi:372 */
		spi1: arduino_spi: spi@40013000 {
			compatible = "st,stm32-spi-fifo",
			             "st,stm32-spi";                                 /* in zephyr/dts/arm/st/g4/stm32g4.dtsi:373 */
			#address-cells = < 0x1 >;                                    /* in zephyr/dts/arm/st/g4/stm32g4.dtsi:374 */
			#size-cells = < 0x0 >;                                       /* in zephyr/dts/arm/st/g4/stm32g4.dtsi:375 */
			reg = < 0x40013000 0x400 >;                                  /* in zephyr/dts/arm/st/g4/stm32g4.dtsi:376 */
			interrupts = < 0x23 0x5 >;                                   /* in zephyr/dts/arm/st/g4/stm32g4.dtsi:377 */
			clocks = < &rcc 0x60 0x1000 >;                               /* in zephyr/dts/arm/st/g4/stm32g4.dtsi:378 */
			pinctrl-0 = < &spi1_sck_pa5 &spi1_miso_pa6 &spi1_mosi_pa7 >; /* in zephyr/boards/st/nucleo_g474re/nucleo_g474re.dts:119 */
			pinctrl-names = "default";                                   /* in zephyr/boards/st/nucleo_g474re/nucleo_g474re.dts:120 */
			cs-gpios = < &gpiob 0x6 0x11 >;                              /* in zephyr/boards/st/nucleo_g474re/nucleo_g474re.dts:121 */
			status = "okay";                                             /* in zephyr/boards/st/nucleo_g474re/nucleo_g474re.dts:122 */
		};

		/* node '/soc/spi@40003800' defined in zephyr/dts/arm/st/g4/stm32g4.dtsi:382 */
		spi2: spi@40003800 {
			compatible = "st,stm32-spi-fifo",
			             "st,stm32-spi";                                                   /* in zephyr/dts/arm/st/g4/stm32g4.dtsi:383 */
			#address-cells = < 0x1 >;                                                      /* in zephyr/dts/arm/st/g4/stm32g4.dtsi:384 */
			#size-cells = < 0x0 >;                                                         /* in zephyr/dts/arm/st/g4/stm32g4.dtsi:385 */
			reg = < 0x40003800 0x400 >;                                                    /* in zephyr/dts/arm/st/g4/stm32g4.dtsi:386 */
			clocks = < &rcc 0x58 0x4000 >;                                                 /* in zephyr/dts/arm/st/g4/stm32g4.dtsi:387 */
			interrupts = < 0x24 0x5 >;                                                     /* in zephyr/dts/arm/st/g4/stm32g4.dtsi:388 */
			pinctrl-0 = < &spi2_nss_pb12 &spi2_sck_pb13 &spi2_miso_pb14 &spi2_mosi_pb15 >; /* in zephyr/boards/st/nucleo_g474re/nucleo_g474re.dts:126 */
			pinctrl-names = "default";                                                     /* in zephyr/boards/st/nucleo_g474re/nucleo_g474re.dts:128 */
			status = "okay";                                                               /* in zephyr/boards/st/nucleo_g474re/nucleo_g474re.dts:129 */
		};

		/* node '/soc/spi@40003c00' defined in zephyr/dts/arm/st/g4/stm32g4.dtsi:392 */
		spi3: spi@40003c00 {
			compatible = "st,stm32-spi-fifo",
			             "st,stm32-spi";                                                   /* in zephyr/dts/arm/st/g4/stm32g4.dtsi:393 */
			#address-cells = < 0x1 >;                                                      /* in zephyr/dts/arm/st/g4/stm32g4.dtsi:394 */
			#size-cells = < 0x0 >;                                                         /* in zephyr/dts/arm/st/g4/stm32g4.dtsi:395 */
			reg = < 0x40003c00 0x400 >;                                                    /* in zephyr/dts/arm/st/g4/stm32g4.dtsi:396 */
			clocks = < &rcc 0x58 0x8000 >;                                                 /* in zephyr/dts/arm/st/g4/stm32g4.dtsi:397 */
			interrupts = < 0x33 0x5 >;                                                     /* in zephyr/dts/arm/st/g4/stm32g4.dtsi:398 */
			pinctrl-0 = < &spi3_nss_pa15 &spi3_sck_pc10 &spi3_miso_pc11 &spi3_mosi_pc12 >; /* in zephyr/boards/st/nucleo_g474re/nucleo_g474re.dts:134 */
			pinctrl-names = "default";                                                     /* in zephyr/boards/st/nucleo_g474re/nucleo_g474re.dts:136 */
			status = "okay";                                                               /* in zephyr/boards/st/nucleo_g474re/nucleo_g474re.dts:137 */
		};

		/* node '/soc/can@40006400' defined in zephyr/dts/arm/st/g4/stm32g4.dtsi:402 */
		fdcan1: can@40006400 {
			compatible = "st,stm32-fdcan";                         /* in zephyr/dts/arm/st/g4/stm32g4.dtsi:403 */
			reg = < 0x40006400 0x400 >,
			      < 0x4000a400 0x350 >;                            /* in zephyr/dts/arm/st/g4/stm32g4.dtsi:404 */
			reg-names = "m_can",
			            "message_ram";                             /* in zephyr/dts/arm/st/g4/stm32g4.dtsi:405 */
			interrupts = < 0x15 0x0 >,
			             < 0x16 0x0 >;                             /* in zephyr/dts/arm/st/g4/stm32g4.dtsi:406 */
			interrupt-names = "int0",
			                  "int1";                              /* in zephyr/dts/arm/st/g4/stm32g4.dtsi:407 */
			bosch,mram-cfg = < 0x0 0x1c 0x8 0x3 0x3 0x0 0x3 0x3 >; /* in zephyr/dts/arm/st/g4/stm32g4.dtsi:409 */
			clocks = < &rcc 0x58 0x2000000 >,
			         < &rcc 0x6 0x380088 >;                        /* in zephyr/boards/st/nucleo_g474re/nucleo_g474re.dts:229 */
			pinctrl-0 = < &fdcan1_rx_pa11 &fdcan1_tx_pa12 >;       /* in zephyr/boards/st/nucleo_g474re/nucleo_g474re.dts:231 */
			pinctrl-names = "default";                             /* in zephyr/boards/st/nucleo_g474re/nucleo_g474re.dts:232 */
			status = "okay";                                       /* in zephyr/boards/st/nucleo_g474re/nucleo_g474re.dts:233 */
		};

		/* node '/soc/timers@40007c00' defined in zephyr/dts/arm/st/g4/stm32g4.dtsi:413 */
		lptim1: stm32_lp_tick_source: timers@40007c00 {
			compatible = "st,stm32-lptim";     /* in zephyr/dts/arm/st/g4/stm32g4.dtsi:414 */
			#address-cells = < 0x1 >;          /* in zephyr/dts/arm/st/g4/stm32g4.dtsi:416 */
			#size-cells = < 0x0 >;             /* in zephyr/dts/arm/st/g4/stm32g4.dtsi:417 */
			reg = < 0x40007c00 0x400 >;        /* in zephyr/dts/arm/st/g4/stm32g4.dtsi:418 */
			interrupts = < 0x31 0x1 >;         /* in zephyr/dts/arm/st/g4/stm32g4.dtsi:419 */
			interrupt-names = "wakeup";        /* in zephyr/dts/arm/st/g4/stm32g4.dtsi:420 */
			clocks = < &rcc 0x58 0x80000000 >,
			         < &rcc 0x3 0x1320088 >;   /* in zephyr/boards/st/nucleo_g474re/nucleo_g474re.dts:162 */
			status = "okay";                   /* in zephyr/boards/st/nucleo_g474re/nucleo_g474re.dts:164 */
		};

		/* node '/soc/timers@40012c00' defined in zephyr/dts/arm/st/g4/stm32g4.dtsi:424 */
		timers1: timers@40012c00 {
			compatible = "st,stm32-timers"; /* in zephyr/dts/arm/st/g4/stm32g4.dtsi:425 */
			reg = < 0x40012c00 0x400 >;     /* in zephyr/dts/arm/st/g4/stm32g4.dtsi:426 */
			clocks = < &rcc 0x60 0x800 >,
			         < &rcc 0xa 0xff >;     /* in zephyr/dts/arm/st/g4/stm32g4.dtsi:427 */
			resets = < &rctl 0x80b >;       /* in zephyr/dts/arm/st/g4/stm32g4.dtsi:429 */
			interrupts = < 0x18 0x0 >,
			             < 0x19 0x0 >,
			             < 0x1a 0x0 >,
			             < 0x1b 0x0 >;      /* in zephyr/dts/arm/st/g4/stm32g4.dtsi:430 */
			interrupt-names = "brk",
			                  "up",
			                  "trgcom",
			                  "cc";         /* in zephyr/dts/arm/st/g4/stm32g4.dtsi:431 */
			st,prescaler = < 0x0 >;         /* in zephyr/dts/arm/st/g4/stm32g4.dtsi:432 */
			status = "disabled";            /* in zephyr/dts/arm/st/g4/stm32g4.dtsi:433 */

			/* node '/soc/timers@40012c00/pwm' defined in zephyr/dts/arm/st/g4/stm32g4.dtsi:435 */
			pwm {
				compatible = "st,stm32-pwm"; /* in zephyr/dts/arm/st/g4/stm32g4.dtsi:436 */
				status = "disabled";         /* in zephyr/dts/arm/st/g4/stm32g4.dtsi:437 */
				#pwm-cells = < 0x3 >;        /* in zephyr/dts/arm/st/g4/stm32g4.dtsi:438 */
			};

			/* node '/soc/timers@40012c00/qdec' defined in zephyr/dts/arm/st/g4/stm32g4.dtsi:441 */
			qdec {
				compatible = "st,stm32-qdec";    /* in zephyr/dts/arm/st/g4/stm32g4.dtsi:442 */
				st,input-filter-level = < 0x0 >; /* in zephyr/dts/arm/st/g4/stm32g4.dtsi:443 */
				status = "disabled";             /* in zephyr/dts/arm/st/g4/stm32g4.dtsi:444 */
			};
		};

		/* node '/soc/timers@40000000' defined in zephyr/dts/arm/st/g4/stm32g4.dtsi:448 */
		timers2: timers@40000000 {
			compatible = "st,stm32-timers"; /* in zephyr/dts/arm/st/g4/stm32g4.dtsi:449 */
			reg = < 0x40000000 0x400 >;     /* in zephyr/dts/arm/st/g4/stm32g4.dtsi:450 */
			clocks = < &rcc 0x58 0x1 >,
			         < &rcc 0x9 0xff >;     /* in zephyr/dts/arm/st/g4/stm32g4.dtsi:451 */
			resets = < &rctl 0x700 >;       /* in zephyr/dts/arm/st/g4/stm32g4.dtsi:453 */
			interrupts = < 0x1c 0x0 >;      /* in zephyr/dts/arm/st/g4/stm32g4.dtsi:454 */
			interrupt-names = "global";     /* in zephyr/dts/arm/st/g4/stm32g4.dtsi:455 */
			st,prescaler = < 0x0 >;         /* in zephyr/dts/arm/st/g4/stm32g4.dtsi:456 */
			status = "okay";                /* in zephyr/boards/st/nucleo_g474re/nucleo_g474re.dts:141 */

			/* node '/soc/timers@40000000/counter' defined in zephyr/dts/arm/st/g4/stm32g4.dtsi:459 */
			counter {
				compatible = "st,stm32-counter"; /* in zephyr/dts/arm/st/g4/stm32g4.dtsi:460 */
				status = "disabled";             /* in zephyr/dts/arm/st/g4/stm32g4.dtsi:461 */
			};

			/* node '/soc/timers@40000000/pwm' defined in zephyr/dts/arm/st/g4/stm32g4.dtsi:464 */
			pwm2: pwm {
				compatible = "st,stm32-pwm";   /* in zephyr/dts/arm/st/g4/stm32g4.dtsi:465 */
				#pwm-cells = < 0x3 >;          /* in zephyr/dts/arm/st/g4/stm32g4.dtsi:467 */
				status = "okay";               /* in zephyr/boards/st/nucleo_g474re/nucleo_g474re.dts:144 */
				pinctrl-0 = < &tim2_ch1_pa5 >; /* in zephyr/boards/st/nucleo_g474re/nucleo_g474re.dts:145 */
				pinctrl-names = "default";     /* in zephyr/boards/st/nucleo_g474re/nucleo_g474re.dts:146 */
				phandle = < 0x2d >;            /* in zephyr/boards/st/nucleo_g474re/nucleo_g474re.dts:40 */
			};

			/* node '/soc/timers@40000000/qdec' defined in zephyr/dts/arm/st/g4/stm32g4.dtsi:470 */
			qdec {
				compatible = "st,stm32-qdec";    /* in zephyr/dts/arm/st/g4/stm32g4.dtsi:471 */
				st,input-filter-level = < 0x0 >; /* in zephyr/dts/arm/st/g4/stm32g4.dtsi:472 */
				status = "disabled";             /* in zephyr/dts/arm/st/g4/stm32g4.dtsi:473 */
			};
		};

		/* node '/soc/timers@40000400' defined in zephyr/dts/arm/st/g4/stm32g4.dtsi:477 */
		timers3: timers@40000400 {
			compatible = "st,stm32-timers"; /* in zephyr/dts/arm/st/g4/stm32g4.dtsi:478 */
			reg = < 0x40000400 0x400 >;     /* in zephyr/dts/arm/st/g4/stm32g4.dtsi:479 */
			clocks = < &rcc 0x58 0x2 >,
			         < &rcc 0x9 0xff >;     /* in zephyr/dts/arm/st/g4/stm32g4.dtsi:480 */
			resets = < &rctl 0x701 >;       /* in zephyr/dts/arm/st/g4/stm32g4.dtsi:482 */
			interrupts = < 0x1d 0x0 >;      /* in zephyr/dts/arm/st/g4/stm32g4.dtsi:483 */
			interrupt-names = "global";     /* in zephyr/dts/arm/st/g4/stm32g4.dtsi:484 */
			st,prescaler = < 0x2710 >;      /* in zephyr/boards/st/nucleo_g474re/nucleo_g474re.dts:151 */
			status = "okay";                /* in zephyr/boards/st/nucleo_g474re/nucleo_g474re.dts:152 */

			/* node '/soc/timers@40000400/counter' defined in zephyr/dts/arm/st/g4/stm32g4.dtsi:488 */
			counter {
				compatible = "st,stm32-counter"; /* in zephyr/dts/arm/st/g4/stm32g4.dtsi:489 */
				status = "disabled";             /* in zephyr/dts/arm/st/g4/stm32g4.dtsi:490 */
			};

			/* node '/soc/timers@40000400/pwm' defined in zephyr/dts/arm/st/g4/stm32g4.dtsi:493 */
			pwm3: pwm {
				compatible = "st,stm32-pwm";   /* in zephyr/dts/arm/st/g4/stm32g4.dtsi:494 */
				#pwm-cells = < 0x3 >;          /* in zephyr/dts/arm/st/g4/stm32g4.dtsi:496 */
				status = "okay";               /* in zephyr/boards/st/nucleo_g474re/nucleo_g474re.dts:155 */
				pinctrl-0 = < &tim3_ch1_pb4 >; /* in zephyr/boards/st/nucleo_g474re/nucleo_g474re.dts:156 */
				pinctrl-names = "default";     /* in zephyr/boards/st/nucleo_g474re/nucleo_g474re.dts:157 */
			};

			/* node '/soc/timers@40000400/qdec' defined in zephyr/dts/arm/st/g4/stm32g4.dtsi:499 */
			qdec {
				compatible = "st,stm32-qdec";    /* in zephyr/dts/arm/st/g4/stm32g4.dtsi:500 */
				st,input-filter-level = < 0x0 >; /* in zephyr/dts/arm/st/g4/stm32g4.dtsi:501 */
				status = "disabled";             /* in zephyr/dts/arm/st/g4/stm32g4.dtsi:502 */
			};
		};

		/* node '/soc/timers@40000800' defined in zephyr/dts/arm/st/g4/stm32g4.dtsi:506 */
		timers4: timers@40000800 {
			compatible = "st,stm32-timers"; /* in zephyr/dts/arm/st/g4/stm32g4.dtsi:507 */
			reg = < 0x40000800 0x400 >;     /* in zephyr/dts/arm/st/g4/stm32g4.dtsi:508 */
			clocks = < &rcc 0x58 0x4 >,
			         < &rcc 0x9 0xff >;     /* in zephyr/dts/arm/st/g4/stm32g4.dtsi:509 */
			resets = < &rctl 0x702 >;       /* in zephyr/dts/arm/st/g4/stm32g4.dtsi:511 */
			interrupts = < 0x1e 0x0 >;      /* in zephyr/dts/arm/st/g4/stm32g4.dtsi:512 */
			interrupt-names = "global";     /* in zephyr/dts/arm/st/g4/stm32g4.dtsi:513 */
			st,prescaler = < 0x0 >;         /* in zephyr/dts/arm/st/g4/stm32g4.dtsi:514 */
			status = "disabled";            /* in zephyr/dts/arm/st/g4/stm32g4.dtsi:515 */

			/* node '/soc/timers@40000800/counter' defined in zephyr/dts/arm/st/g4/stm32g4.dtsi:517 */
			counter {
				compatible = "st,stm32-counter"; /* in zephyr/dts/arm/st/g4/stm32g4.dtsi:518 */
				status = "disabled";             /* in zephyr/dts/arm/st/g4/stm32g4.dtsi:519 */
			};

			/* node '/soc/timers@40000800/pwm' defined in zephyr/dts/arm/st/g4/stm32g4.dtsi:522 */
			pwm {
				compatible = "st,stm32-pwm"; /* in zephyr/dts/arm/st/g4/stm32g4.dtsi:523 */
				status = "disabled";         /* in zephyr/dts/arm/st/g4/stm32g4.dtsi:524 */
				#pwm-cells = < 0x3 >;        /* in zephyr/dts/arm/st/g4/stm32g4.dtsi:525 */
			};

			/* node '/soc/timers@40000800/qdec' defined in zephyr/dts/arm/st/g4/stm32g4.dtsi:528 */
			qdec {
				compatible = "st,stm32-qdec";    /* in zephyr/dts/arm/st/g4/stm32g4.dtsi:529 */
				st,input-filter-level = < 0x0 >; /* in zephyr/dts/arm/st/g4/stm32g4.dtsi:530 */
				status = "disabled";             /* in zephyr/dts/arm/st/g4/stm32g4.dtsi:531 */
			};
		};

		/* node '/soc/timers@40001000' defined in zephyr/dts/arm/st/g4/stm32g4.dtsi:535 */
		timers6: timers@40001000 {
			compatible = "st,stm32-timers"; /* in zephyr/dts/arm/st/g4/stm32g4.dtsi:536 */
			reg = < 0x40001000 0x400 >;     /* in zephyr/dts/arm/st/g4/stm32g4.dtsi:537 */
			clocks = < &rcc 0x58 0x10 >,
			         < &rcc 0x9 0xff >;     /* in zephyr/dts/arm/st/g4/stm32g4.dtsi:538 */
			resets = < &rctl 0x704 >;       /* in zephyr/dts/arm/st/g4/stm32g4.dtsi:540 */
			interrupts = < 0x36 0x0 >;      /* in zephyr/dts/arm/st/g4/stm32g4.dtsi:541 */
			interrupt-names = "global";     /* in zephyr/dts/arm/st/g4/stm32g4.dtsi:542 */
			st,prescaler = < 0x0 >;         /* in zephyr/dts/arm/st/g4/stm32g4.dtsi:543 */
			status = "disabled";            /* in zephyr/dts/arm/st/g4/stm32g4.dtsi:544 */
		};

		/* node '/soc/timers@40001400' defined in zephyr/dts/arm/st/g4/stm32g4.dtsi:547 */
		timers7: timers@40001400 {
			compatible = "st,stm32-timers"; /* in zephyr/dts/arm/st/g4/stm32g4.dtsi:548 */
			reg = < 0x40001400 0x400 >;     /* in zephyr/dts/arm/st/g4/stm32g4.dtsi:549 */
			clocks = < &rcc 0x58 0x20 >,
			         < &rcc 0x9 0xff >;     /* in zephyr/dts/arm/st/g4/stm32g4.dtsi:550 */
			resets = < &rctl 0x705 >;       /* in zephyr/dts/arm/st/g4/stm32g4.dtsi:552 */
			interrupts = < 0x37 0x0 >;      /* in zephyr/dts/arm/st/g4/stm32g4.dtsi:553 */
			interrupt-names = "global";     /* in zephyr/dts/arm/st/g4/stm32g4.dtsi:554 */
			st,prescaler = < 0x0 >;         /* in zephyr/dts/arm/st/g4/stm32g4.dtsi:555 */
			status = "disabled";            /* in zephyr/dts/arm/st/g4/stm32g4.dtsi:556 */
		};

		/* node '/soc/timers@40013400' defined in zephyr/dts/arm/st/g4/stm32g4.dtsi:559 */
		timers8: timers@40013400 {
			compatible = "st,stm32-timers"; /* in zephyr/dts/arm/st/g4/stm32g4.dtsi:560 */
			reg = < 0x40013400 0x400 >;     /* in zephyr/dts/arm/st/g4/stm32g4.dtsi:561 */
			clocks = < &rcc 0x60 0x2000 >,
			         < &rcc 0xa 0xff >;     /* in zephyr/dts/arm/st/g4/stm32g4.dtsi:562 */
			resets = < &rctl 0x80d >;       /* in zephyr/dts/arm/st/g4/stm32g4.dtsi:564 */
			interrupts = < 0x2b 0x0 >,
			             < 0x2c 0x0 >,
			             < 0x2d 0x0 >,
			             < 0x2e 0x0 >;      /* in zephyr/dts/arm/st/g4/stm32g4.dtsi:565 */
			interrupt-names = "brk",
			                  "up",
			                  "trgcom",
			                  "cc";         /* in zephyr/dts/arm/st/g4/stm32g4.dtsi:566 */
			st,prescaler = < 0x0 >;         /* in zephyr/dts/arm/st/g4/stm32g4.dtsi:567 */
			status = "disabled";            /* in zephyr/dts/arm/st/g4/stm32g4.dtsi:568 */

			/* node '/soc/timers@40013400/pwm' defined in zephyr/dts/arm/st/g4/stm32g4.dtsi:570 */
			pwm {
				compatible = "st,stm32-pwm"; /* in zephyr/dts/arm/st/g4/stm32g4.dtsi:571 */
				status = "disabled";         /* in zephyr/dts/arm/st/g4/stm32g4.dtsi:572 */
				#pwm-cells = < 0x3 >;        /* in zephyr/dts/arm/st/g4/stm32g4.dtsi:573 */
			};

			/* node '/soc/timers@40013400/qdec' defined in zephyr/dts/arm/st/g4/stm32g4.dtsi:576 */
			qdec {
				compatible = "st,stm32-qdec";    /* in zephyr/dts/arm/st/g4/stm32g4.dtsi:577 */
				st,input-filter-level = < 0x0 >; /* in zephyr/dts/arm/st/g4/stm32g4.dtsi:578 */
				status = "disabled";             /* in zephyr/dts/arm/st/g4/stm32g4.dtsi:579 */
			};
		};

		/* node '/soc/timers@40014000' defined in zephyr/dts/arm/st/g4/stm32g4.dtsi:583 */
		timers15: timers@40014000 {
			compatible = "st,stm32-timers"; /* in zephyr/dts/arm/st/g4/stm32g4.dtsi:584 */
			reg = < 0x40014000 0x400 >;     /* in zephyr/dts/arm/st/g4/stm32g4.dtsi:585 */
			clocks = < &rcc 0x60 0x10000 >,
			         < &rcc 0xa 0xff >;     /* in zephyr/dts/arm/st/g4/stm32g4.dtsi:586 */
			resets = < &rctl 0x810 >;       /* in zephyr/dts/arm/st/g4/stm32g4.dtsi:588 */
			interrupts = < 0x18 0x0 >;      /* in zephyr/dts/arm/st/g4/stm32g4.dtsi:589 */
			interrupt-names = "global";     /* in zephyr/dts/arm/st/g4/stm32g4.dtsi:590 */
			st,prescaler = < 0x0 >;         /* in zephyr/dts/arm/st/g4/stm32g4.dtsi:591 */
			status = "disabled";            /* in zephyr/dts/arm/st/g4/stm32g4.dtsi:592 */

			/* node '/soc/timers@40014000/pwm' defined in zephyr/dts/arm/st/g4/stm32g4.dtsi:594 */
			pwm {
				compatible = "st,stm32-pwm"; /* in zephyr/dts/arm/st/g4/stm32g4.dtsi:595 */
				status = "disabled";         /* in zephyr/dts/arm/st/g4/stm32g4.dtsi:596 */
				#pwm-cells = < 0x3 >;        /* in zephyr/dts/arm/st/g4/stm32g4.dtsi:597 */
			};

			/* node '/soc/timers@40014000/counter' defined in zephyr/dts/arm/st/g4/stm32g4.dtsi:600 */
			counter {
				compatible = "st,stm32-counter"; /* in zephyr/dts/arm/st/g4/stm32g4.dtsi:601 */
				status = "disabled";             /* in zephyr/dts/arm/st/g4/stm32g4.dtsi:602 */
			};
		};

		/* node '/soc/timers@40014400' defined in zephyr/dts/arm/st/g4/stm32g4.dtsi:606 */
		timers16: timers@40014400 {
			compatible = "st,stm32-timers"; /* in zephyr/dts/arm/st/g4/stm32g4.dtsi:607 */
			reg = < 0x40014400 0x400 >;     /* in zephyr/dts/arm/st/g4/stm32g4.dtsi:608 */
			clocks = < &rcc 0x60 0x20000 >,
			         < &rcc 0xa 0xff >;     /* in zephyr/dts/arm/st/g4/stm32g4.dtsi:609 */
			resets = < &rctl 0x811 >;       /* in zephyr/dts/arm/st/g4/stm32g4.dtsi:611 */
			interrupts = < 0x19 0x0 >;      /* in zephyr/dts/arm/st/g4/stm32g4.dtsi:612 */
			interrupt-names = "global";     /* in zephyr/dts/arm/st/g4/stm32g4.dtsi:613 */
			st,prescaler = < 0x0 >;         /* in zephyr/dts/arm/st/g4/stm32g4.dtsi:614 */
			status = "disabled";            /* in zephyr/dts/arm/st/g4/stm32g4.dtsi:615 */

			/* node '/soc/timers@40014400/pwm' defined in zephyr/dts/arm/st/g4/stm32g4.dtsi:617 */
			pwm {
				compatible = "st,stm32-pwm"; /* in zephyr/dts/arm/st/g4/stm32g4.dtsi:618 */
				status = "disabled";         /* in zephyr/dts/arm/st/g4/stm32g4.dtsi:619 */
				#pwm-cells = < 0x3 >;        /* in zephyr/dts/arm/st/g4/stm32g4.dtsi:620 */
			};

			/* node '/soc/timers@40014400/counter' defined in zephyr/dts/arm/st/g4/stm32g4.dtsi:623 */
			counter {
				compatible = "st,stm32-counter"; /* in zephyr/dts/arm/st/g4/stm32g4.dtsi:624 */
				status = "disabled";             /* in zephyr/dts/arm/st/g4/stm32g4.dtsi:625 */
			};
		};

		/* node '/soc/timers@40014800' defined in zephyr/dts/arm/st/g4/stm32g4.dtsi:629 */
		timers17: timers@40014800 {
			compatible = "st,stm32-timers"; /* in zephyr/dts/arm/st/g4/stm32g4.dtsi:630 */
			reg = < 0x40014800 0x400 >;     /* in zephyr/dts/arm/st/g4/stm32g4.dtsi:631 */
			clocks = < &rcc 0x60 0x40000 >,
			         < &rcc 0xa 0xff >;     /* in zephyr/dts/arm/st/g4/stm32g4.dtsi:632 */
			resets = < &rctl 0x812 >;       /* in zephyr/dts/arm/st/g4/stm32g4.dtsi:634 */
			interrupts = < 0x1a 0x0 >;      /* in zephyr/dts/arm/st/g4/stm32g4.dtsi:635 */
			interrupt-names = "global";     /* in zephyr/dts/arm/st/g4/stm32g4.dtsi:636 */
			st,prescaler = < 0x0 >;         /* in zephyr/dts/arm/st/g4/stm32g4.dtsi:637 */
			status = "disabled";            /* in zephyr/dts/arm/st/g4/stm32g4.dtsi:638 */

			/* node '/soc/timers@40014800/pwm' defined in zephyr/dts/arm/st/g4/stm32g4.dtsi:640 */
			pwm {
				compatible = "st,stm32-pwm"; /* in zephyr/dts/arm/st/g4/stm32g4.dtsi:641 */
				status = "disabled";         /* in zephyr/dts/arm/st/g4/stm32g4.dtsi:642 */
				#pwm-cells = < 0x3 >;        /* in zephyr/dts/arm/st/g4/stm32g4.dtsi:643 */
			};

			/* node '/soc/timers@40014800/counter' defined in zephyr/dts/arm/st/g4/stm32g4.dtsi:646 */
			counter {
				compatible = "st,stm32-counter"; /* in zephyr/dts/arm/st/g4/stm32g4.dtsi:647 */
				status = "disabled";             /* in zephyr/dts/arm/st/g4/stm32g4.dtsi:648 */
			};
		};

		/* node '/soc/rtc@40002800' defined in zephyr/dts/arm/st/g4/stm32g4.dtsi:652 */
		rtc: rtc@40002800 {
			compatible = "st,stm32-rtc";     /* in zephyr/dts/arm/st/g4/stm32g4.dtsi:653 */
			reg = < 0x40002800 0x400 >;      /* in zephyr/dts/arm/st/g4/stm32g4.dtsi:654 */
			interrupts = < 0x29 0x0 >;       /* in zephyr/dts/arm/st/g4/stm32g4.dtsi:655 */
			prescaler = < 0x8000 >;          /* in zephyr/dts/arm/st/g4/stm32g4.dtsi:657 */
			alarms-count = < 0x2 >;          /* in zephyr/dts/arm/st/g4/stm32g4.dtsi:658 */
			alrm-exti-line = < 0x11 >;       /* in zephyr/dts/arm/st/g4/stm32g4.dtsi:659 */
			clocks = < &rcc 0x58 0x400 >,
			         < &rcc 0x3 0x2280090 >; /* in zephyr/boards/st/nucleo_g474re/nucleo_g474re.dts:168 */
			status = "okay";                 /* in zephyr/boards/st/nucleo_g474re/nucleo_g474re.dts:170 */
		};

		/* node '/soc/rng@50060800' defined in zephyr/dts/arm/st/g4/stm32g4.dtsi:663 */
		rng: rng@50060800 {
			compatible = "st,stm32-rng";      /* in zephyr/dts/arm/st/g4/stm32g4.dtsi:664 */
			reg = < 0x50060800 0x400 >;       /* in zephyr/dts/arm/st/g4/stm32g4.dtsi:665 */
			interrupts = < 0x5a 0x0 >;        /* in zephyr/dts/arm/st/g4/stm32g4.dtsi:666 */
			clocks = < &rcc 0x4c 0x4000000 >; /* in zephyr/dts/arm/st/g4/stm32g4.dtsi:667 */
			status = "okay";                  /* in zephyr/boards/st/nucleo_g474re/nucleo_g474re.dts:207 */
		};

		/* node '/soc/usb@40005c00' defined in zephyr/dts/arm/st/g4/stm32g4.dtsi:671 */
		usb: usb@40005c00 {
			compatible = "st,stm32-usb";     /* in zephyr/dts/arm/st/g4/stm32g4.dtsi:672 */
			reg = < 0x40005c00 0x400 >;      /* in zephyr/dts/arm/st/g4/stm32g4.dtsi:673 */
			interrupts = < 0x14 0x0 >,
			             < 0x13 0x0 >;       /* in zephyr/dts/arm/st/g4/stm32g4.dtsi:674 */
			interrupt-names = "usb",
			                  "usbhp";       /* in zephyr/dts/arm/st/g4/stm32g4.dtsi:675 */
			num-bidir-endpoints = < 0x8 >;   /* in zephyr/dts/arm/st/g4/stm32g4.dtsi:676 */
			ram-size = < 0x400 >;            /* in zephyr/dts/arm/st/g4/stm32g4.dtsi:677 */
			maximum-speed = "full-speed";    /* in zephyr/dts/arm/st/g4/stm32g4.dtsi:678 */
			phys = < &usb_fs_phy >;          /* in zephyr/dts/arm/st/g4/stm32g4.dtsi:679 */
			clocks = < &rcc 0x58 0x800000 >,
			         < &rcc 0x5 0x3a0088 >;  /* in zephyr/dts/arm/st/g4/stm32g4.dtsi:680 */
			status = "disabled";             /* in zephyr/dts/arm/st/g4/stm32g4.dtsi:682 */
		};

		/* node '/soc/dma@40020000' defined in zephyr/dts/arm/st/g4/stm32g4.dtsi:685 */
		dma1: dma@40020000 {
			compatible = "st,stm32-dma-v2";                                                      /* in zephyr/dts/arm/st/g4/stm32g4.dtsi:686 */
			#dma-cells = < 0x3 >;                                                                /* in zephyr/dts/arm/st/g4/stm32g4.dtsi:687 */
			reg = < 0x40020000 0x400 >;                                                          /* in zephyr/dts/arm/st/g4/stm32g4.dtsi:688 */
			clocks = < &rcc 0x48 0x1 >;                                                          /* in zephyr/dts/arm/st/g4/stm32g4.dtsi:689 */
			dma-offset = < 0x0 >;                                                                /* in zephyr/dts/arm/st/g4/stm32g4.dtsi:690 */
			status = "disabled";                                                                 /* in zephyr/dts/arm/st/g4/stm32g4.dtsi:691 */
			interrupts = < 0xb 0x0 0xc 0x0 0xd 0x0 0xe 0x0 0xf 0x0 0x10 0x0 0x11 0x0 0x60 0x0 >; /* in zephyr/dts/arm/st/g4/stm32g491.dtsi:50 */
			dma-requests = < 0x8 >;                                                              /* in zephyr/dts/arm/st/g4/stm32g491.dtsi:51 */
			phandle = < 0x20 >;                                                                  /* in zephyr/dts/arm/st/g4/stm32g4.dtsi:727 */
		};

		/* node '/soc/dma@40020400' defined in zephyr/dts/arm/st/g4/stm32g4.dtsi:694 */
		dma2: dma@40020400 {
			compatible = "st,stm32-dma-v2";                                                           /* in zephyr/dts/arm/st/g4/stm32g4.dtsi:695 */
			#dma-cells = < 0x3 >;                                                                     /* in zephyr/dts/arm/st/g4/stm32g4.dtsi:696 */
			reg = < 0x40020400 0x400 >;                                                               /* in zephyr/dts/arm/st/g4/stm32g4.dtsi:697 */
			clocks = < &rcc 0x48 0x2 >;                                                               /* in zephyr/dts/arm/st/g4/stm32g4.dtsi:698 */
			status = "disabled";                                                                      /* in zephyr/dts/arm/st/g4/stm32g4.dtsi:699 */
			interrupts = < 0x38 0x0 0x39 0x0 0x3a 0x0 0x3b 0x0 0x3c 0x0 0x61 0x0 0x62 0x0 0x63 0x0 >; /* in zephyr/dts/arm/st/g4/stm32g491.dtsi:55 */
			dma-requests = < 0x8 >;                                                                   /* in zephyr/dts/arm/st/g4/stm32g491.dtsi:56 */
			dma-offset = < 0x8 >;                                                                     /* in zephyr/dts/arm/st/g4/stm32g491.dtsi:57 */
		};

		/* node '/soc/dmamux@40020800' defined in zephyr/dts/arm/st/g4/stm32g4.dtsi:702 */
		dmamux1: dmamux@40020800 {
			compatible = "st,stm32-dmamux"; /* in zephyr/dts/arm/st/g4/stm32g4.dtsi:703 */
			#dma-cells = < 0x3 >;           /* in zephyr/dts/arm/st/g4/stm32g4.dtsi:704 */
			reg = < 0x40020800 0x400 >;     /* in zephyr/dts/arm/st/g4/stm32g4.dtsi:705 */
			interrupts = < 0x5e 0x0 >;      /* in zephyr/dts/arm/st/g4/stm32g4.dtsi:706 */
			clocks = < &rcc 0x48 0x4 >;     /* in zephyr/dts/arm/st/g4/stm32g4.dtsi:707 */
			dma-generators = < 0x4 >;       /* in zephyr/dts/arm/st/g4/stm32g4.dtsi:708 */
			dma-requests = < 0x6f >;        /* in zephyr/dts/arm/st/g4/stm32g4.dtsi:709 */
			status = "disabled";            /* in zephyr/dts/arm/st/g4/stm32g4.dtsi:710 */
			dma-channels = < 0x10 >;        /* in zephyr/dts/arm/st/g4/stm32g491.dtsi:61 */
		};

		/* node '/soc/ucpd@4000a000' defined in zephyr/dts/arm/st/g4/stm32g4.dtsi:713 */
		ucpd1: ucpd@4000a000 {
			compatible = "st,stm32-ucpd"; /* in zephyr/dts/arm/st/g4/stm32g4.dtsi:714 */
			reg = < 0x4000a000 0x400 >;   /* in zephyr/dts/arm/st/g4/stm32g4.dtsi:715 */
			clocks = < &rcc 0x58 0x10 >;  /* in zephyr/dts/arm/st/g4/stm32g4.dtsi:716 */
			interrupts = < 0x3f 0x0 >;    /* in zephyr/dts/arm/st/g4/stm32g4.dtsi:717 */
			status = "disabled";          /* in zephyr/dts/arm/st/g4/stm32g4.dtsi:718 */
		};

		/* node '/soc/sai1@40015404' defined in zephyr/dts/arm/st/g4/stm32g4.dtsi:721 */
		sai1_a: sai1@40015404 {
			compatible = "st,stm32-sai";       /* in zephyr/dts/arm/st/g4/stm32g4.dtsi:722 */
			#address-cells = < 0x1 >;          /* in zephyr/dts/arm/st/g4/stm32g4.dtsi:723 */
			#size-cells = < 0x0 >;             /* in zephyr/dts/arm/st/g4/stm32g4.dtsi:724 */
			reg = < 0x40015404 0x20 >;         /* in zephyr/dts/arm/st/g4/stm32g4.dtsi:725 */
			clocks = < &rcc 0x60 0x200000 >;   /* in zephyr/dts/arm/st/g4/stm32g4.dtsi:726 */
			dmas = < &dma1 0x1 0x6c 0x22800 >; /* in zephyr/dts/arm/st/g4/stm32g4.dtsi:727 */
			status = "disabled";               /* in zephyr/dts/arm/st/g4/stm32g4.dtsi:729 */
		};

		/* node '/soc/sai1@40015424' defined in zephyr/dts/arm/st/g4/stm32g4.dtsi:732 */
		sai1_b: sai1@40015424 {
			compatible = "st,stm32-sai";       /* in zephyr/dts/arm/st/g4/stm32g4.dtsi:733 */
			#address-cells = < 0x1 >;          /* in zephyr/dts/arm/st/g4/stm32g4.dtsi:734 */
			#size-cells = < 0x0 >;             /* in zephyr/dts/arm/st/g4/stm32g4.dtsi:735 */
			reg = < 0x40015424 0x20 >;         /* in zephyr/dts/arm/st/g4/stm32g4.dtsi:736 */
			clocks = < &rcc 0x60 0x200000 >;   /* in zephyr/dts/arm/st/g4/stm32g4.dtsi:737 */
			dmas = < &dma1 0x2 0x6d 0x22800 >; /* in zephyr/dts/arm/st/g4/stm32g4.dtsi:738 */
			status = "disabled";               /* in zephyr/dts/arm/st/g4/stm32g4.dtsi:740 */
		};

		/* node '/soc/comparator@40010200' defined in zephyr/dts/arm/st/g4/stm32g4.dtsi:743 */
		comp1: comparator@40010200 {
			compatible = "st,stm32g4-comp",
			             "st,stm32-comp";   /* in zephyr/dts/arm/st/g4/stm32g4.dtsi:744 */
			reg = < 0x40010200 0x4 >;       /* in zephyr/dts/arm/st/g4/stm32g4.dtsi:745 */
			interrupts = < 0x40 0x0 >;      /* in zephyr/dts/arm/st/g4/stm32g4.dtsi:746 */
			st,exti-line = < 0x15 >;        /* in zephyr/dts/arm/st/g4/stm32g4.dtsi:747 */
			clocks = < &rcc 0x60 0x1 >;     /* in zephyr/dts/arm/st/g4/stm32g4.dtsi:748 */
			status = "disabled";            /* in zephyr/dts/arm/st/g4/stm32g4.dtsi:749 */
		};

		/* node '/soc/comparator@40010204' defined in zephyr/dts/arm/st/g4/stm32g4.dtsi:752 */
		comp2: comparator@40010204 {
			compatible = "st,stm32g4-comp",
			             "st,stm32-comp";   /* in zephyr/dts/arm/st/g4/stm32g4.dtsi:753 */
			reg = < 0x40010204 0x4 >;       /* in zephyr/dts/arm/st/g4/stm32g4.dtsi:754 */
			interrupts = < 0x40 0x0 >;      /* in zephyr/dts/arm/st/g4/stm32g4.dtsi:755 */
			st,exti-line = < 0x16 >;        /* in zephyr/dts/arm/st/g4/stm32g4.dtsi:756 */
			clocks = < &rcc 0x60 0x1 >;     /* in zephyr/dts/arm/st/g4/stm32g4.dtsi:757 */
			status = "disabled";            /* in zephyr/dts/arm/st/g4/stm32g4.dtsi:758 */
		};

		/* node '/soc/can@40006800' defined in zephyr/dts/arm/st/g4/stm32g491.dtsi:14 */
		fdcan2: can@40006800 {
			compatible = "st,stm32-fdcan";                           /* in zephyr/dts/arm/st/g4/stm32g491.dtsi:15 */
			reg = < 0x40006800 0x400 >,
			      < 0x4000a400 0x6a0 >;                              /* in zephyr/dts/arm/st/g4/stm32g491.dtsi:16 */
			reg-names = "m_can",
			            "message_ram";                               /* in zephyr/dts/arm/st/g4/stm32g491.dtsi:17 */
			interrupts = < 0x56 0x0 >,
			             < 0x57 0x0 >;                               /* in zephyr/dts/arm/st/g4/stm32g491.dtsi:18 */
			interrupt-names = "int0",
			                  "int1";                                /* in zephyr/dts/arm/st/g4/stm32g491.dtsi:19 */
			clocks = < &rcc 0x58 0x2000000 >;                        /* in zephyr/dts/arm/st/g4/stm32g491.dtsi:20 */
			bosch,mram-cfg = < 0x350 0x1c 0x8 0x3 0x3 0x0 0x3 0x3 >; /* in zephyr/dts/arm/st/g4/stm32g491.dtsi:21 */
			status = "disabled";                                     /* in zephyr/dts/arm/st/g4/stm32g491.dtsi:22 */
		};

		/* node '/soc/timers@40015000' defined in zephyr/dts/arm/st/g4/stm32g491.dtsi:25 */
		timers20: timers@40015000 {
			compatible = "st,stm32-timers";  /* in zephyr/dts/arm/st/g4/stm32g491.dtsi:26 */
			reg = < 0x40015000 0x400 >;      /* in zephyr/dts/arm/st/g4/stm32g491.dtsi:27 */
			clocks = < &rcc 0x60 0x100000 >,
			         < &rcc 0xa 0xff >;      /* in zephyr/dts/arm/st/g4/stm32g491.dtsi:28 */
			resets = < &rctl 0x814 >;        /* in zephyr/dts/arm/st/g4/stm32g491.dtsi:30 */
			interrupts = < 0x4d 0x0 >,
			             < 0x4e 0x0 >,
			             < 0x4f 0x0 >,
			             < 0x50 0x0 >;       /* in zephyr/dts/arm/st/g4/stm32g491.dtsi:31 */
			interrupt-names = "brk",
			                  "up",
			                  "trgcom",
			                  "cc";          /* in zephyr/dts/arm/st/g4/stm32g491.dtsi:32 */
			st,prescaler = < 0x0 >;          /* in zephyr/dts/arm/st/g4/stm32g491.dtsi:33 */
			status = "disabled";             /* in zephyr/dts/arm/st/g4/stm32g491.dtsi:34 */

			/* node '/soc/timers@40015000/pwm' defined in zephyr/dts/arm/st/g4/stm32g491.dtsi:36 */
			pwm {
				compatible = "st,stm32-pwm"; /* in zephyr/dts/arm/st/g4/stm32g491.dtsi:37 */
				status = "disabled";         /* in zephyr/dts/arm/st/g4/stm32g491.dtsi:38 */
				#pwm-cells = < 0x3 >;        /* in zephyr/dts/arm/st/g4/stm32g491.dtsi:39 */
			};

			/* node '/soc/timers@40015000/qdec' defined in zephyr/dts/arm/st/g4/stm32g491.dtsi:42 */
			qdec {
				compatible = "st,stm32-qdec";    /* in zephyr/dts/arm/st/g4/stm32g491.dtsi:43 */
				st,input-filter-level = < 0x0 >; /* in zephyr/dts/arm/st/g4/stm32g491.dtsi:44 */
				status = "disabled";             /* in zephyr/dts/arm/st/g4/stm32g491.dtsi:45 */
			};
		};

		/* node '/soc/adc@50000400' defined in zephyr/dts/arm/st/g4/stm32g491.dtsi:64 */
		adc3: adc@50000400 {
			compatible = "st,stm32-adc";                                /* in zephyr/dts/arm/st/g4/stm32g491.dtsi:65 */
			reg = < 0x50000400 0x100 >;                                 /* in zephyr/dts/arm/st/g4/stm32g491.dtsi:66 */
			clocks = < &rcc 0x4c 0x4000 >;                              /* in zephyr/dts/arm/st/g4/stm32g491.dtsi:67 */
			clock-names = "adcx";                                       /* in zephyr/dts/arm/st/g4/stm32g491.dtsi:68 */
			interrupts = < 0x2f 0x0 >;                                  /* in zephyr/dts/arm/st/g4/stm32g491.dtsi:69 */
			#io-channel-cells = < 0x1 >;                                /* in zephyr/dts/arm/st/g4/stm32g491.dtsi:70 */
			resolutions = < 0x60630c 0x51630c 0x42630c 0x33630c >;      /* in zephyr/dts/arm/st/g4/stm32g491.dtsi:71 */
			sampling-times = < 0x3 0x7 0xd 0x19 0x30 0x5d 0xf8 0x281 >; /* in zephyr/dts/arm/st/g4/stm32g491.dtsi:75 */
			st,adc-sequencer = "programmable";                          /* in zephyr/dts/arm/st/g4/stm32g491.dtsi:76 */
			st,adc-oversampler = "minimal";                             /* in zephyr/dts/arm/st/g4/stm32g491.dtsi:77 */
			st,adc-internal-regulator = "startup-sw-delay";             /* in zephyr/dts/arm/st/g4/stm32g491.dtsi:78 */
			st,adc-has-deep-powerdown;                                  /* in zephyr/dts/arm/st/g4/stm32g491.dtsi:79 */
			st,adc-has-differential-support;                            /* in zephyr/dts/arm/st/g4/stm32g491.dtsi:80 */
			status = "disabled";                                        /* in zephyr/dts/arm/st/g4/stm32g491.dtsi:81 */
		};

		/* node '/soc/serial@40005000' defined in zephyr/dts/arm/st/g4/stm32g491.dtsi:84 */
		uart5: serial@40005000 {
			compatible = "st,stm32-uart";    /* in zephyr/dts/arm/st/g4/stm32g491.dtsi:85 */
			reg = < 0x40005000 0x400 >;      /* in zephyr/dts/arm/st/g4/stm32g491.dtsi:86 */
			clocks = < &rcc 0x58 0x100000 >; /* in zephyr/dts/arm/st/g4/stm32g491.dtsi:87 */
			resets = < &rctl 0x714 >;        /* in zephyr/dts/arm/st/g4/stm32g491.dtsi:88 */
			interrupts = < 0x35 0x0 >;       /* in zephyr/dts/arm/st/g4/stm32g491.dtsi:89 */
			status = "disabled";             /* in zephyr/dts/arm/st/g4/stm32g491.dtsi:90 */
		};

		/* node '/soc/spi@a0001000' defined in zephyr/dts/arm/st/g4/stm32g491.dtsi:93 */
		quadspi: spi@a0001000 {
			compatible = "st,stm32-qspi";    /* in zephyr/dts/arm/st/g4/stm32g491.dtsi:94 */
			#address-cells = < 0x1 >;        /* in zephyr/dts/arm/st/g4/stm32g491.dtsi:95 */
			#size-cells = < 0x0 >;           /* in zephyr/dts/arm/st/g4/stm32g491.dtsi:96 */
			reg = < 0xa0001000 0x400 >,
			      < 0x90000000 0x10000000 >; /* in zephyr/dts/arm/st/g4/stm32g491.dtsi:97 */
			interrupts = < 0x5f 0x0 >;       /* in zephyr/dts/arm/st/g4/stm32g491.dtsi:98 */
			clocks = < &rcc 0x50 0x100 >;    /* in zephyr/dts/arm/st/g4/stm32g491.dtsi:99 */
			status = "disabled";             /* in zephyr/dts/arm/st/g4/stm32g491.dtsi:100 */
		};

		/* node '/soc/timers@40000c00' defined in zephyr/dts/arm/st/g4/stm32g473.dtsi:14 */
		timers5: timers@40000c00 {
			compatible = "st,stm32-timers"; /* in zephyr/dts/arm/st/g4/stm32g473.dtsi:15 */
			reg = < 0x40000c00 0x400 >;     /* in zephyr/dts/arm/st/g4/stm32g473.dtsi:16 */
			clocks = < &rcc 0x58 0x8 >,
			         < &rcc 0x9 0xff >;     /* in zephyr/dts/arm/st/g4/stm32g473.dtsi:17 */
			resets = < &rctl 0x703 >;       /* in zephyr/dts/arm/st/g4/stm32g473.dtsi:19 */
			interrupts = < 0x32 0x0 >;      /* in zephyr/dts/arm/st/g4/stm32g473.dtsi:20 */
			interrupt-names = "global";     /* in zephyr/dts/arm/st/g4/stm32g473.dtsi:21 */
			st,prescaler = < 0x0 >;         /* in zephyr/dts/arm/st/g4/stm32g473.dtsi:22 */
			status = "disabled";            /* in zephyr/dts/arm/st/g4/stm32g473.dtsi:23 */

			/* node '/soc/timers@40000c00/pwm' defined in zephyr/dts/arm/st/g4/stm32g473.dtsi:25 */
			pwm {
				compatible = "st,stm32-pwm"; /* in zephyr/dts/arm/st/g4/stm32g473.dtsi:26 */
				status = "disabled";         /* in zephyr/dts/arm/st/g4/stm32g473.dtsi:27 */
				#pwm-cells = < 0x3 >;        /* in zephyr/dts/arm/st/g4/stm32g473.dtsi:28 */
			};

			/* node '/soc/timers@40000c00/qdec' defined in zephyr/dts/arm/st/g4/stm32g473.dtsi:31 */
			qdec {
				compatible = "st,stm32-qdec";    /* in zephyr/dts/arm/st/g4/stm32g473.dtsi:32 */
				st,input-filter-level = < 0x0 >; /* in zephyr/dts/arm/st/g4/stm32g473.dtsi:33 */
				status = "disabled";             /* in zephyr/dts/arm/st/g4/stm32g473.dtsi:34 */
			};
		};

		/* node '/soc/adc@50000500' defined in zephyr/dts/arm/st/g4/stm32g473.dtsi:38 */
		adc4: adc@50000500 {
			compatible = "st,stm32-adc";                                /* in zephyr/dts/arm/st/g4/stm32g473.dtsi:39 */
			reg = < 0x50000500 0x100 >;                                 /* in zephyr/dts/arm/st/g4/stm32g473.dtsi:40 */
			clocks = < &rcc 0x4c 0x4000 >;                              /* in zephyr/dts/arm/st/g4/stm32g473.dtsi:41 */
			clock-names = "adcx";                                       /* in zephyr/dts/arm/st/g4/stm32g473.dtsi:42 */
			interrupts = < 0x3d 0x0 >;                                  /* in zephyr/dts/arm/st/g4/stm32g473.dtsi:43 */
			#io-channel-cells = < 0x1 >;                                /* in zephyr/dts/arm/st/g4/stm32g473.dtsi:44 */
			resolutions = < 0x60630c 0x51630c 0x42630c 0x33630c >;      /* in zephyr/dts/arm/st/g4/stm32g473.dtsi:45 */
			sampling-times = < 0x3 0x7 0xd 0x19 0x30 0x5d 0xf8 0x281 >; /* in zephyr/dts/arm/st/g4/stm32g473.dtsi:49 */
			st,adc-sequencer = "programmable";                          /* in zephyr/dts/arm/st/g4/stm32g473.dtsi:50 */
			st,adc-oversampler = "minimal";                             /* in zephyr/dts/arm/st/g4/stm32g473.dtsi:51 */
			st,adc-internal-regulator = "startup-sw-delay";             /* in zephyr/dts/arm/st/g4/stm32g473.dtsi:52 */
			st,adc-has-deep-powerdown;                                  /* in zephyr/dts/arm/st/g4/stm32g473.dtsi:53 */
			st,adc-has-differential-support;                            /* in zephyr/dts/arm/st/g4/stm32g473.dtsi:54 */
			status = "disabled";                                        /* in zephyr/dts/arm/st/g4/stm32g473.dtsi:55 */
		};

		/* node '/soc/adc@50000600' defined in zephyr/dts/arm/st/g4/stm32g473.dtsi:58 */
		adc5: adc@50000600 {
			compatible = "st,stm32-adc";                                /* in zephyr/dts/arm/st/g4/stm32g473.dtsi:59 */
			reg = < 0x50000600 0x100 >;                                 /* in zephyr/dts/arm/st/g4/stm32g473.dtsi:60 */
			clocks = < &rcc 0x4c 0x4000 >;                              /* in zephyr/dts/arm/st/g4/stm32g473.dtsi:61 */
			clock-names = "adcx";                                       /* in zephyr/dts/arm/st/g4/stm32g473.dtsi:62 */
			interrupts = < 0x3e 0x0 >;                                  /* in zephyr/dts/arm/st/g4/stm32g473.dtsi:63 */
			#io-channel-cells = < 0x1 >;                                /* in zephyr/dts/arm/st/g4/stm32g473.dtsi:64 */
			resolutions = < 0x60630c 0x51630c 0x42630c 0x33630c >;      /* in zephyr/dts/arm/st/g4/stm32g473.dtsi:65 */
			sampling-times = < 0x3 0x7 0xd 0x19 0x30 0x5d 0xf8 0x281 >; /* in zephyr/dts/arm/st/g4/stm32g473.dtsi:69 */
			st,adc-sequencer = "programmable";                          /* in zephyr/dts/arm/st/g4/stm32g473.dtsi:70 */
			st,adc-oversampler = "minimal";                             /* in zephyr/dts/arm/st/g4/stm32g473.dtsi:71 */
			st,adc-internal-regulator = "startup-sw-delay";             /* in zephyr/dts/arm/st/g4/stm32g473.dtsi:72 */
			st,adc-has-deep-powerdown;                                  /* in zephyr/dts/arm/st/g4/stm32g473.dtsi:73 */
			st,adc-has-differential-support;                            /* in zephyr/dts/arm/st/g4/stm32g473.dtsi:74 */
			status = "disabled";                                        /* in zephyr/dts/arm/st/g4/stm32g473.dtsi:75 */
		};

		/* node '/soc/spi@40013c00' defined in zephyr/dts/arm/st/g4/stm32g473.dtsi:78 */
		spi4: spi@40013c00 {
			compatible = "st,stm32-spi-fifo",
			             "st,stm32-spi";      /* in zephyr/dts/arm/st/g4/stm32g473.dtsi:79 */
			#address-cells = < 0x1 >;         /* in zephyr/dts/arm/st/g4/stm32g473.dtsi:80 */
			#size-cells = < 0x0 >;            /* in zephyr/dts/arm/st/g4/stm32g473.dtsi:81 */
			reg = < 0x40013c00 0x400 >;       /* in zephyr/dts/arm/st/g4/stm32g473.dtsi:82 */
			clocks = < &rcc 0x60 0x8000 >;    /* in zephyr/dts/arm/st/g4/stm32g473.dtsi:83 */
			interrupts = < 0x54 0x5 >;        /* in zephyr/dts/arm/st/g4/stm32g473.dtsi:84 */
			status = "disabled";              /* in zephyr/dts/arm/st/g4/stm32g473.dtsi:85 */
		};

		/* node '/soc/dac@50000c00' defined in zephyr/dts/arm/st/g4/stm32g473.dtsi:88 */
		dac2: dac@50000c00 {
			compatible = "st,stm32-dac";    /* in zephyr/dts/arm/st/g4/stm32g473.dtsi:89 */
			reg = < 0x50000c00 0x400 >;     /* in zephyr/dts/arm/st/g4/stm32g473.dtsi:90 */
			clocks = < &rcc 0x4c 0x20000 >; /* in zephyr/dts/arm/st/g4/stm32g473.dtsi:91 */
			status = "disabled";            /* in zephyr/dts/arm/st/g4/stm32g473.dtsi:92 */
			#io-channel-cells = < 0x1 >;    /* in zephyr/dts/arm/st/g4/stm32g473.dtsi:93 */
		};

		/* node '/soc/dac@50001400' defined in zephyr/dts/arm/st/g4/stm32g473.dtsi:96 */
		dac4: dac@50001400 {
			compatible = "st,stm32-dac";    /* in zephyr/dts/arm/st/g4/stm32g473.dtsi:97 */
			reg = < 0x50001400 0x400 >;     /* in zephyr/dts/arm/st/g4/stm32g473.dtsi:98 */
			clocks = < &rcc 0x4c 0x80000 >; /* in zephyr/dts/arm/st/g4/stm32g473.dtsi:99 */
			status = "disabled";            /* in zephyr/dts/arm/st/g4/stm32g473.dtsi:100 */
			#io-channel-cells = < 0x1 >;    /* in zephyr/dts/arm/st/g4/stm32g473.dtsi:101 */
		};

		/* node '/soc/i2c@40008400' defined in zephyr/dts/arm/st/g4/stm32g473.dtsi:104 */
		i2c4: i2c@40008400 {
			compatible = "st,stm32-i2c-v2"; /* in zephyr/dts/arm/st/g4/stm32g473.dtsi:105 */
			clock-frequency = < 0x186a0 >;  /* in zephyr/dts/arm/st/g4/stm32g473.dtsi:106 */
			#address-cells = < 0x1 >;       /* in zephyr/dts/arm/st/g4/stm32g473.dtsi:107 */
			#size-cells = < 0x0 >;          /* in zephyr/dts/arm/st/g4/stm32g473.dtsi:108 */
			reg = < 0x40008400 0x400 >;     /* in zephyr/dts/arm/st/g4/stm32g473.dtsi:109 */
			clocks = < &rcc 0x5c 0x2 >;     /* in zephyr/dts/arm/st/g4/stm32g473.dtsi:110 */
			interrupts = < 0x52 0x0 >,
			             < 0x53 0x0 >;      /* in zephyr/dts/arm/st/g4/stm32g473.dtsi:111 */
			interrupt-names = "event",
			                  "error";      /* in zephyr/dts/arm/st/g4/stm32g473.dtsi:112 */
			status = "disabled";            /* in zephyr/dts/arm/st/g4/stm32g473.dtsi:113 */
			phandle = < 0x28 >;             /* in zephyr/dts/arm/st/g4/stm32g473.dtsi:132 */
		};

		/* node '/soc/can@40006c00' defined in zephyr/dts/arm/st/g4/stm32g473.dtsi:116 */
		fdcan3: can@40006c00 {
			compatible = "st,stm32-fdcan";                           /* in zephyr/dts/arm/st/g4/stm32g473.dtsi:117 */
			reg = < 0x40006c00 0x400 >,
			      < 0x4000a400 0x9f0 >;                              /* in zephyr/dts/arm/st/g4/stm32g473.dtsi:118 */
			reg-names = "m_can",
			            "message_ram";                               /* in zephyr/dts/arm/st/g4/stm32g473.dtsi:119 */
			interrupts = < 0x58 0x0 >,
			             < 0x59 0x0 >;                               /* in zephyr/dts/arm/st/g4/stm32g473.dtsi:120 */
			interrupt-names = "int0",
			                  "int1";                                /* in zephyr/dts/arm/st/g4/stm32g473.dtsi:121 */
			clocks = < &rcc 0x58 0x2000000 >;                        /* in zephyr/dts/arm/st/g4/stm32g473.dtsi:122 */
			bosch,mram-cfg = < 0x6a0 0x1c 0x8 0x3 0x3 0x0 0x3 0x3 >; /* in zephyr/dts/arm/st/g4/stm32g473.dtsi:123 */
			status = "disabled";                                     /* in zephyr/dts/arm/st/g4/stm32g473.dtsi:124 */
		};
	};

	/* node '/cpus' defined in zephyr/dts/arm/st/g4/stm32g4.dtsi:31 */
	cpus {
		#address-cells = < 0x1 >; /* in zephyr/dts/arm/st/g4/stm32g4.dtsi:32 */
		#size-cells = < 0x0 >;    /* in zephyr/dts/arm/st/g4/stm32g4.dtsi:33 */

		/* node '/cpus/cpu@0' defined in zephyr/dts/arm/st/g4/stm32g4.dtsi:35 */
		cpu0: cpu@0 {
			device_type = "cpu";                  /* in zephyr/dts/arm/st/g4/stm32g4.dtsi:36 */
			compatible = "arm,cortex-m4f";        /* in zephyr/dts/arm/st/g4/stm32g4.dtsi:37 */
			reg = < 0x0 >;                        /* in zephyr/dts/arm/st/g4/stm32g4.dtsi:38 */
			cpu-power-states = < &stop0 &stop1 >; /* in zephyr/dts/arm/st/g4/stm32g4.dtsi:39 */
		};

		/* node '/cpus/power-states' defined in zephyr/dts/arm/st/g4/stm32g4.dtsi:42 */
		power-states {

			/* node '/cpus/power-states/state0' defined in zephyr/dts/arm/st/g4/stm32g4.dtsi:43 */
			stop0: state0 {
				compatible = "zephyr,power-state";    /* in zephyr/dts/arm/st/g4/stm32g4.dtsi:44 */
				power-state-name = "suspend-to-idle"; /* in zephyr/dts/arm/st/g4/stm32g4.dtsi:45 */
				substate-id = < 0x1 >;                /* in zephyr/dts/arm/st/g4/stm32g4.dtsi:46 */
				min-residency-us = < 0x14 >;          /* in zephyr/dts/arm/st/g4/stm32g4.dtsi:47 */
				phandle = < 0x21 >;                   /* in zephyr/dts/arm/st/g4/stm32g4.dtsi:39 */
			};

			/* node '/cpus/power-states/state1' defined in zephyr/dts/arm/st/g4/stm32g4.dtsi:50 */
			stop1: state1 {
				compatible = "zephyr,power-state";    /* in zephyr/dts/arm/st/g4/stm32g4.dtsi:51 */
				power-state-name = "suspend-to-idle"; /* in zephyr/dts/arm/st/g4/stm32g4.dtsi:52 */
				substate-id = < 0x2 >;                /* in zephyr/dts/arm/st/g4/stm32g4.dtsi:53 */
				min-residency-us = < 0x64 >;          /* in zephyr/dts/arm/st/g4/stm32g4.dtsi:54 */
				phandle = < 0x22 >;                   /* in zephyr/dts/arm/st/g4/stm32g4.dtsi:39 */
			};
		};
	};

	/* node '/memory@20000000' defined in zephyr/dts/arm/st/g4/stm32g4.dtsi:59 */
	sram0: memory@20000000 {
		compatible = "zephyr,memory-region",
		             "mmio-sram";            /* in zephyr/dts/arm/st/g4/stm32g4.dtsi:60 */
		zephyr,memory-region = "SRAM0";      /* in zephyr/dts/arm/st/g4/stm32g4.dtsi:61 */
		reg = < 0x20000000 0x20000 >;        /* in zephyr/dts/arm/st/g4/stm32g474Xe.dtsi:10 */
	};

	/* node '/clocks' defined in zephyr/dts/arm/st/g4/stm32g4.dtsi:64 */
	clocks {

		/* node '/clocks/clk-hse' defined in zephyr/dts/arm/st/g4/stm32g4.dtsi:65 */
		clk_hse: clk-hse {
			#clock-cells = < 0x0 >;            /* in zephyr/dts/arm/st/g4/stm32g4.dtsi:66 */
			compatible = "st,stm32-hse-clock"; /* in zephyr/dts/arm/st/g4/stm32g4.dtsi:67 */
			clock-frequency = < 0x16e3600 >;   /* in zephyr/boards/st/nucleo_g474re/nucleo_g474re.dts:75 */
			status = "okay";                   /* in zephyr/boards/st/nucleo_g474re/nucleo_g474re.dts:76 */
			phandle = < 0x23 >;                /* in zephyr/boards/st/nucleo_g474re/nucleo_g474re.dts:85 */
		};

		/* node '/clocks/clk-hsi' defined in zephyr/dts/arm/st/g4/stm32g4.dtsi:71 */
		clk_hsi: clk-hsi {
			#clock-cells = < 0x0 >;         /* in zephyr/dts/arm/st/g4/stm32g4.dtsi:72 */
			compatible = "fixed-clock";     /* in zephyr/dts/arm/st/g4/stm32g4.dtsi:73 */
			clock-frequency = < 0xf42400 >; /* in zephyr/dts/arm/st/g4/stm32g4.dtsi:74 */
			status = "disabled";            /* in zephyr/dts/arm/st/g4/stm32g4.dtsi:75 */
		};

		/* node '/clocks/clk-hsi48' defined in zephyr/dts/arm/st/g4/stm32g4.dtsi:78 */
		clk_hsi48: clk-hsi48 {
			#clock-cells = < 0x0 >;          /* in zephyr/dts/arm/st/g4/stm32g4.dtsi:79 */
			compatible = "fixed-clock";      /* in zephyr/dts/arm/st/g4/stm32g4.dtsi:80 */
			clock-frequency = < 0x2dc6c00 >; /* in zephyr/dts/arm/st/g4/stm32g4.dtsi:81 */
			status = "okay";                 /* in zephyr/boards/st/nucleo_g474re/nucleo_g474re.dts:71 */
		};

		/* node '/clocks/clk-lse' defined in zephyr/dts/arm/st/g4/stm32g4.dtsi:85 */
		clk_lse: clk-lse {
			#clock-cells = < 0x0 >;            /* in zephyr/dts/arm/st/g4/stm32g4.dtsi:86 */
			compatible = "st,stm32-lse-clock"; /* in zephyr/dts/arm/st/g4/stm32g4.dtsi:87 */
			clock-frequency = < 0x8000 >;      /* in zephyr/dts/arm/st/g4/stm32g4.dtsi:88 */
			driving-capability = < 0x0 >;      /* in zephyr/dts/arm/st/g4/stm32g4.dtsi:89 */
			status = "disabled";               /* in zephyr/dts/arm/st/g4/stm32g4.dtsi:90 */
		};

		/* node '/clocks/clk-lsi' defined in zephyr/dts/arm/st/g4/stm32g4.dtsi:93 */
		clk_lsi: clk-lsi {
			#clock-cells = < 0x0 >;       /* in zephyr/dts/arm/st/g4/stm32g4.dtsi:94 */
			compatible = "fixed-clock";   /* in zephyr/dts/arm/st/g4/stm32g4.dtsi:95 */
			clock-frequency = < 0x7d00 >; /* in zephyr/dts/arm/st/g4/stm32g4.dtsi:96 */
			status = "okay";              /* in zephyr/boards/st/nucleo_g474re/nucleo_g474re.dts:67 */
		};

		/* node '/clocks/pll' defined in zephyr/dts/arm/st/g4/stm32g4.dtsi:100 */
		pll: pll {
			#clock-cells = < 0x0 >;              /* in zephyr/dts/arm/st/g4/stm32g4.dtsi:101 */
			compatible = "st,stm32g4-pll-clock"; /* in zephyr/dts/arm/st/g4/stm32g4.dtsi:102 */
			div-m = < 0x6 >;                     /* in zephyr/boards/st/nucleo_g474re/nucleo_g474re.dts:80 */
			mul-n = < 0x55 >;                    /* in zephyr/boards/st/nucleo_g474re/nucleo_g474re.dts:81 */
			div-p = < 0x7 >;                     /* in zephyr/boards/st/nucleo_g474re/nucleo_g474re.dts:82 */
			div-q = < 0x2 >;                     /* in zephyr/boards/st/nucleo_g474re/nucleo_g474re.dts:83 */
			div-r = < 0x2 >;                     /* in zephyr/boards/st/nucleo_g474re/nucleo_g474re.dts:84 */
			clocks = < &clk_hse >;               /* in zephyr/boards/st/nucleo_g474re/nucleo_g474re.dts:85 */
			status = "okay";                     /* in zephyr/boards/st/nucleo_g474re/nucleo_g474re.dts:86 */
			phandle = < 0x5 >;                   /* in zephyr/boards/st/nucleo_g474re/nucleo_g474re.dts:90 */
		};
	};

	/* node '/dietemp' defined in zephyr/dts/arm/st/g4/stm32g4.dtsi:762 */
	die_temp: dietemp {
		compatible = "st,stm32-temp-cal"; /* in zephyr/dts/arm/st/g4/stm32g4.dtsi:763 */
		ts-cal1-addr = < 0x1fff75a8 >;    /* in zephyr/dts/arm/st/g4/stm32g4.dtsi:764 */
		ts-cal2-addr = < 0x1fff75ca >;    /* in zephyr/dts/arm/st/g4/stm32g4.dtsi:765 */
		ts-cal1-temp = < 0x1e >;          /* in zephyr/dts/arm/st/g4/stm32g4.dtsi:766 */
		ts-cal2-temp = < 0x82 >;          /* in zephyr/dts/arm/st/g4/stm32g4.dtsi:767 */
		ts-cal-vrefanalog = < 0xbb8 >;    /* in zephyr/dts/arm/st/g4/stm32g4.dtsi:768 */
		io-channels = < &adc1 0x10 >;     /* in zephyr/dts/arm/st/g4/stm32g4.dtsi:769 */
		status = "okay";                  /* in zephyr/boards/st/nucleo_g474re/nucleo_g474re.dts:219 */
	};

	/* node '/vref' defined in zephyr/dts/arm/st/g4/stm32g4.dtsi:773 */
	vref: vref {
		compatible = "st,stm32-vref";      /* in zephyr/dts/arm/st/g4/stm32g4.dtsi:774 */
		vrefint-cal-addr = < 0x1fff75aa >; /* in zephyr/dts/arm/st/g4/stm32g4.dtsi:775 */
		vrefint-cal-mv = < 0xbb8 >;        /* in zephyr/dts/arm/st/g4/stm32g4.dtsi:776 */
		io-channels = < &adc1 0x12 >;      /* in zephyr/dts/arm/st/g4/stm32g4.dtsi:777 */
		status = "okay";                   /* in zephyr/boards/st/nucleo_g474re/nucleo_g474re.dts:237 */
	};

	/* node '/vbat' defined in zephyr/dts/arm/st/g4/stm32g4.dtsi:781 */
	vbat: vbat {
		compatible = "st,stm32-vbat"; /* in zephyr/dts/arm/st/g4/stm32g4.dtsi:782 */
		ratio = < 0x3 >;              /* in zephyr/dts/arm/st/g4/stm32g4.dtsi:783 */
		io-channels = < &adc1 0x11 >; /* in zephyr/dts/arm/st/g4/stm32g4.dtsi:784 */
		status = "okay";              /* in zephyr/boards/st/nucleo_g474re/nucleo_g474re.dts:241 */
	};

	/* node '/usbphy' defined in zephyr/dts/arm/st/g4/stm32g4.dtsi:788 */
	usb_fs_phy: usbphy {
		compatible = "usb-nop-xceiv"; /* in zephyr/dts/arm/st/g4/stm32g4.dtsi:789 */
		#phy-cells = < 0x0 >;         /* in zephyr/dts/arm/st/g4/stm32g4.dtsi:790 */
		phandle = < 0x1f >;           /* in zephyr/dts/arm/st/g4/stm32g4.dtsi:679 */
	};

	/* node '/smbus1' defined in zephyr/dts/arm/st/g4/stm32g4.dtsi:793 */
	smbus1: smbus1 {
		compatible = "st,stm32-smbus"; /* in zephyr/dts/arm/st/g4/stm32g4.dtsi:794 */
		#address-cells = < 0x1 >;      /* in zephyr/dts/arm/st/g4/stm32g4.dtsi:795 */
		#size-cells = < 0x0 >;         /* in zephyr/dts/arm/st/g4/stm32g4.dtsi:796 */
		i2c = < &i2c1 >;               /* in zephyr/dts/arm/st/g4/stm32g4.dtsi:797 */
		status = "disabled";           /* in zephyr/dts/arm/st/g4/stm32g4.dtsi:798 */
	};

	/* node '/smbus2' defined in zephyr/dts/arm/st/g4/stm32g4.dtsi:801 */
	smbus2: smbus2 {
		compatible = "st,stm32-smbus"; /* in zephyr/dts/arm/st/g4/stm32g4.dtsi:802 */
		#address-cells = < 0x1 >;      /* in zephyr/dts/arm/st/g4/stm32g4.dtsi:803 */
		#size-cells = < 0x0 >;         /* in zephyr/dts/arm/st/g4/stm32g4.dtsi:804 */
		i2c = < &i2c2 >;               /* in zephyr/dts/arm/st/g4/stm32g4.dtsi:805 */
		status = "disabled";           /* in zephyr/dts/arm/st/g4/stm32g4.dtsi:806 */
	};

	/* node '/smbus3' defined in zephyr/dts/arm/st/g4/stm32g4.dtsi:809 */
	smbus3: smbus3 {
		compatible = "st,stm32-smbus"; /* in zephyr/dts/arm/st/g4/stm32g4.dtsi:810 */
		#address-cells = < 0x1 >;      /* in zephyr/dts/arm/st/g4/stm32g4.dtsi:811 */
		#size-cells = < 0x0 >;         /* in zephyr/dts/arm/st/g4/stm32g4.dtsi:812 */
		i2c = < &i2c3 >;               /* in zephyr/dts/arm/st/g4/stm32g4.dtsi:813 */
		status = "disabled";           /* in zephyr/dts/arm/st/g4/stm32g4.dtsi:814 */
	};

	/* node '/smbus4' defined in zephyr/dts/arm/st/g4/stm32g473.dtsi:128 */
	smbus4: smbus4 {
		compatible = "st,stm32-smbus"; /* in zephyr/dts/arm/st/g4/stm32g473.dtsi:129 */
		#address-cells = < 0x1 >;      /* in zephyr/dts/arm/st/g4/stm32g473.dtsi:130 */
		#size-cells = < 0x0 >;         /* in zephyr/dts/arm/st/g4/stm32g473.dtsi:131 */
		i2c = < &i2c4 >;               /* in zephyr/dts/arm/st/g4/stm32g473.dtsi:132 */
		status = "disabled";           /* in zephyr/dts/arm/st/g4/stm32g473.dtsi:133 */
	};

	/* node '/connector' defined in zephyr/boards/st/nucleo_g474re/arduino_r3_connector.dtsi:10 */
	arduino_header: connector {
		compatible = "arduino-header-r3";          /* in zephyr/boards/st/nucleo_g474re/arduino_r3_connector.dtsi:11 */
		#gpio-cells = < 0x2 >;                     /* in zephyr/boards/st/nucleo_g474re/arduino_r3_connector.dtsi:12 */
		gpio-map-mask = < 0xffffffff 0xffffffc0 >; /* in zephyr/boards/st/nucleo_g474re/arduino_r3_connector.dtsi:13 */
		gpio-map-pass-thru = < 0x0 0x3f >;         /* in zephyr/boards/st/nucleo_g474re/arduino_r3_connector.dtsi:14 */
		gpio-map = < 0x0 0x0 &gpioa 0x0 0x0 >,
		           < 0x1 0x0 &gpioa 0x1 0x0 >,
		           < 0x2 0x0 &gpioa 0x4 0x0 >,
		           < 0x3 0x0 &gpiob 0x0 0x0 >,
		           < 0x4 0x0 &gpioc 0x1 0x0 >,
		           < 0x5 0x0 &gpioc 0x0 0x0 >,
		           < 0x6 0x0 &gpioc 0x5 0x0 >,
		           < 0x7 0x0 &gpioc 0x4 0x0 >,
		           < 0x8 0x0 &gpioa 0xa 0x0 >,
		           < 0x9 0x0 &gpiob 0x3 0x0 >,
		           < 0xa 0x0 &gpiob 0x5 0x0 >,
		           < 0xb 0x0 &gpiob 0x4 0x0 >,
		           < 0xc 0x0 &gpiob 0xa 0x0 >,
		           < 0xd 0x0 &gpioa 0x8 0x0 >,
		           < 0xe 0x0 &gpioa 0x9 0x0 >,
		           < 0xf 0x0 &gpioc 0x7 0x0 >,
		           < 0x10 0x0 &gpiob 0x6 0x0 >,
		           < 0x11 0x0 &gpioa 0x7 0x0 >,
		           < 0x12 0x0 &gpioa 0x6 0x0 >,
		           < 0x13 0x0 &gpioa 0x5 0x0 >,
		           < 0x14 0x0 &gpiob 0x9 0x0 >,
		           < 0x15 0x0 &gpiob 0x8 0x0 >;    /* in zephyr/boards/st/nucleo_g474re/arduino_r3_connector.dtsi:15 */
	};

	/* node '/st-morpho-header' defined in zephyr/boards/st/nucleo_g474re/st_morpho_connector.dtsi:10 */
	st_morpho_header: st-morpho-header {
		compatible = "st-morpho-header";        /* in zephyr/boards/st/nucleo_g474re/st_morpho_connector.dtsi:11 */
		#gpio-cells = < 0x2 >;                  /* in zephyr/boards/st/nucleo_g474re/st_morpho_connector.dtsi:12 */
		gpio-map-mask = < 0xff 0x0 >;           /* in zephyr/boards/st/nucleo_g474re/st_morpho_connector.dtsi:13 */
		gpio-map-pass-thru = < 0x0 0x7f >;      /* in zephyr/boards/st/nucleo_g474re/st_morpho_connector.dtsi:14 */
		gpio-map = < 0x0 0x0 &gpioc 0xa 0x0 >,
		           < 0x1 0x0 &gpioc 0xb 0x0 >,
		           < 0x2 0x0 &gpioc 0xc 0x0 >,
		           < 0x3 0x0 &gpiod 0x2 0x0 >,
		           < 0xc 0x0 &gpioa 0xd 0x0 >,
		           < 0xe 0x0 &gpioa 0xe 0x0 >,
		           < 0x10 0x0 &gpioa 0xf 0x0 >,
		           < 0x14 0x0 &gpiob 0x7 0x0 >,
		           < 0x16 0x0 &gpioc 0xd 0x0 >,
		           < 0x18 0x0 &gpioc 0xe 0x0 >,
		           < 0x1a 0x0 &gpioc 0xf 0x0 >,
		           < 0x1b 0x0 &gpioa 0x0 0x0 >,
		           < 0x1c 0x0 &gpiof 0x0 0x0 >,
		           < 0x1d 0x0 &gpioa 0x1 0x0 >,
		           < 0x1e 0x0 &gpiof 0x1 0x0 >,
		           < 0x1f 0x0 &gpioa 0x4 0x0 >,
		           < 0x21 0x0 &gpiob 0x0 0x0 >,
		           < 0x22 0x0 &gpioc 0x2 0x0 >,
		           < 0x23 0x0 &gpioc 0x1 0x0 >,
		           < 0x24 0x0 &gpioc 0x3 0x0 >,
		           < 0x25 0x0 &gpioc 0x0 0x0 >,
		           < 0x48 0x0 &gpioc 0x9 0x0 >,
		           < 0x49 0x0 &gpioc 0x8 0x0 >,
		           < 0x4a 0x0 &gpiob 0x8 0x0 >,
		           < 0x4b 0x0 &gpioc 0x6 0x0 >,
		           < 0x4c 0x0 &gpiob 0x9 0x0 >,
		           < 0x4d 0x0 &gpioc 0x5 0x0 >,
		           < 0x52 0x0 &gpioa 0x5 0x0 >,
		           < 0x53 0x0 &gpioa 0xc 0x0 >,
		           < 0x54 0x0 &gpioa 0x6 0x0 >,
		           < 0x55 0x0 &gpioa 0xb 0x0 >,
		           < 0x56 0x0 &gpioa 0x7 0x0 >,
		           < 0x57 0x0 &gpiob 0xc 0x0 >,
		           < 0x58 0x0 &gpiob 0x6 0x0 >,
		           < 0x59 0x0 &gpiob 0xb 0x0 >,
		           < 0x5a 0x0 &gpioc 0x7 0x0 >,
		           < 0x5c 0x0 &gpioa 0x9 0x0 >,
		           < 0x5d 0x0 &gpiob 0x2 0x0 >,
		           < 0x5e 0x0 &gpioa 0x8 0x0 >,
		           < 0x5f 0x0 &gpiob 0x1 0x0 >,
		           < 0x60 0x0 &gpiob 0xa 0x0 >,
		           < 0x61 0x0 &gpiob 0xf 0x0 >,
		           < 0x62 0x0 &gpiob 0x4 0x0 >,
		           < 0x63 0x0 &gpiob 0xe 0x0 >,
		           < 0x64 0x0 &gpiob 0x5 0x0 >,
		           < 0x65 0x0 &gpiob 0xd 0x0 >,
		           < 0x66 0x0 &gpiob 0x3 0x0 >,
		           < 0x68 0x0 &gpioa 0xa 0x0 >,
		           < 0x69 0x0 &gpioc 0x4 0x0 >,
		           < 0x6a 0x0 &gpioa 0x2 0x0 >,
		           < 0x6c 0x0 &gpioa 0x3 0x0 >; /* in zephyr/boards/st/nucleo_g474re/st_morpho_connector.dtsi:15 */
	};

	/* node '/leds' defined in zephyr/boards/st/nucleo_g474re/nucleo_g474re.dts:27 */
	leds: leds {
		compatible = "gpio-leds"; /* in zephyr/boards/st/nucleo_g474re/nucleo_g474re.dts:28 */

		/* node '/leds/led_0' defined in zephyr/boards/st/nucleo_g474re/nucleo_g474re.dts:30 */
		green_led: led_0 {
			gpios = < &gpioa 0x5 0x0 >; /* in zephyr/boards/st/nucleo_g474re/nucleo_g474re.dts:31 */
			label = "User LD2";         /* in zephyr/boards/st/nucleo_g474re/nucleo_g474re.dts:32 */
		};
	};

	/* node '/pwmleds' defined in zephyr/boards/st/nucleo_g474re/nucleo_g474re.dts:36 */
	pwmleds {
		compatible = "pwm-leds"; /* in zephyr/boards/st/nucleo_g474re/nucleo_g474re.dts:37 */

		/* node '/pwmleds/green_pwm_led' defined in zephyr/boards/st/nucleo_g474re/nucleo_g474re.dts:39 */
		green_pwm_led: green_pwm_led {
			pwms = < &pwm2 0x1 0x1312d00 0x0 >; /* in zephyr/boards/st/nucleo_g474re/nucleo_g474re.dts:40 */
		};
	};

	/* node '/gpio_keys' defined in zephyr/boards/st/nucleo_g474re/nucleo_g474re.dts:44 */
	gpio_keys {
		compatible = "gpio-keys"; /* in zephyr/boards/st/nucleo_g474re/nucleo_g474re.dts:45 */

		/* node '/gpio_keys/button' defined in zephyr/boards/st/nucleo_g474re/nucleo_g474re.dts:47 */
		user_button: button {
			label = "User";             /* in zephyr/boards/st/nucleo_g474re/nucleo_g474re.dts:48 */
			gpios = < &gpioc 0xd 0x1 >; /* in zephyr/boards/st/nucleo_g474re/nucleo_g474re.dts:49 */
			zephyr,code = < 0xb >;      /* in zephyr/boards/st/nucleo_g474re/nucleo_g474re.dts:50 */
		};
	};
};
